VERSION ""

NS_ :

BS_:

BU_: EON RDC SZL VGSG Gate1 RFK FLA RAD1 CAS CID AHM HKL HUD EKP DWA DSC SM_BF GWS VDM DDE1 ACI CCC SM_FA CTM LDM RSE MRSZ VDA EDCK ZBE EGS ACC Kombi IHKA ARS ACSM FZD PGS NVC AFS DME FRMFA EMF FKA VSW EPS PDC DKG SMG EHC SZM KGM Diagnosetool_PT_CAN Diagnosetool_K_CAN_System Vector__XXX XXX ABS DIA FRM RAD TEL

CM_ "Source <https://github.com/dzid26/opendbc-BMW-E8x-E9x>";
CM_ "Some data copied from https://github.com/HeinrichG-V12/E65_ReverseEngineering/ and MSD81 document"
CM_ "Tool32 reference https://www.bimmerforums.com/forum/showthread.php?2298830-E90-Can-bus-project-(E60-E65-E87-)&p=29628499#post29628499"
CM_ "Some data copied from great MK60e5_Development_DBC.dbc: https://www.m5board.com/posts/7693749/"
CM_ "License MIT";
CM_ "BMW E90 K-CAN 100 kbit/s";
CM_ "Additional signals merged from https://github.com/nberlette/canbus";

BO_ 128 SYNC: 5 XXX
 SG_ State1 : 16|8@1+ (1,0) [0|255] "" Vector__XXX
 SG_ State2 : 24|4@1+ (1,0) [0|15] "" Vector__XXX
 SG_ Counter_128 : 28|4@1+ (1,0) [0|15] "" Vector__XXX

BO_ 133 Synchronization_SC_VDA: 8 DSC

BO_ 168 EngineAndBrake: 8 DME
 SG_ Checksum_0xa8 : 0|8@1+ (1,0) [0|0] "" EGS,DSC
 SG_ Counter_0xa8 : 8|4@1+ (1,0) [0|15] "" EGS,DSC
 SG_ TORQ_AVL : 12|12@1- (0.5,0) [-1024|1023.5] "Nm" EGS,DSC
 SG_ ST_TORQ_AVL : 27|4@0+ (1,0) [0|15] "" EGS,DSC
 SG_ TORQ_AVL_DMEE : 28|12@1- (0.5,0) [-1024|1023.5] "Nm" EGS,DSC
 SG_ ST_SW_CLT : 41|2@0+ (1,0) [0|3] "" EGS,DSC
 SG_ ST_RTIR : 43|2@0+ (1,0) [0|3] "" EGS,DSC
 SG_ ST_DMEA_SWO : 44|2@1+ (1,0) [0|0] "" EGS,DSC
 SG_ RCPT_ACC_SWO_SYS_DME : 47|2@0+ (1,0) [0|3] "" EGS,DSC
 SG_ ST_RCPT_ENG_ACC : 48|2@1+ (1,0) [0|0] "" EGS,DSC
 SG_ ST_RCPT_ENG_ARS : 50|2@1+ (1,0) [0|0] "" EGS,DSC
 SG_ ST_RCPT_ENG_DSC : 52|2@1+ (1,0) [0|0] "" EGS,DSC
 SG_ ST_RCPT_ENG_EGS : 54|2@1+ (1,0) [0|0] "" EGS,DSC
 SG_ ST_OBD_CTFN_GRB : 60|5@0+ (1,0) [0|31] "" EGS,DSC
 SG_ BrakePressed : 61|1@0+ (1,0) [0|1] "" EGS,DSC
 SG_ BrakeActive : 62|1@0+ (1,0) [0|1] "" EGS,DSC
 SG_ BrakeStatusInvalid : 63|1@1+ (1,0) [0|1] "" EGS,DSC

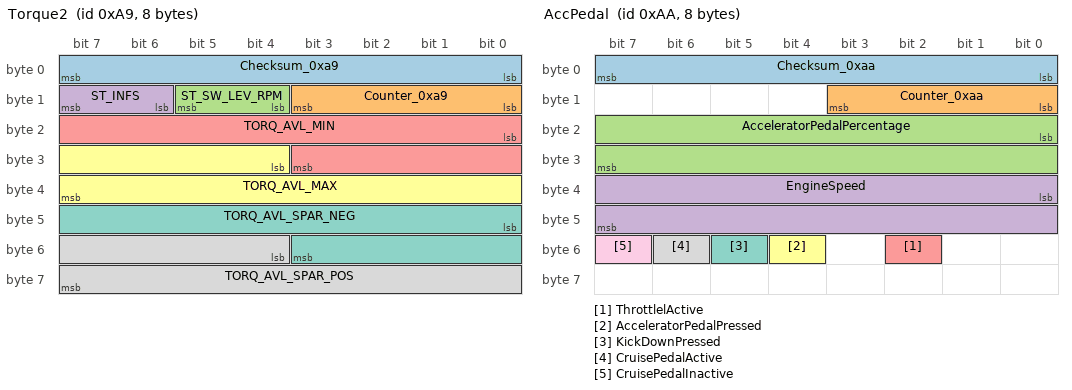
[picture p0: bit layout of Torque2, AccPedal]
BO_ 169 Torque2: 8 DME
 SG_ Checksum_0xa9 : 0|8@1+ (1,0) [0|0] "" EGS,DSC
 SG_ Counter_0xa9 : 8|4@1+ (1,0) [0|0] "" EGS,DSC
 SG_ ST_SW_LEV_RPM : 12|2@1+ (1,0) [0|0] "" EGS,DSC
 SG_ ST_INFS : 14|2@1+ (1,0) [0|0] "" EGS,DSC
 SG_ TORQ_AVL_MIN : 16|12@1- (0.5,0) [-1023.5|1023.5] "Nm" EGS,DSC
 SG_ TORQ_AVL_MAX : 28|12@1- (0.5,0) [-1023.5|1023.5] "Nm" EGS,DSC
 SG_ TORQ_AVL_SPAR_NEG : 40|12@1- (0.5,0) [-1023.5|1023.5] "Nm" EGS,DSC
 SG_ TORQ_AVL_SPAR_POS : 52|12@1- (0.5,0) [-1023.5|1023.5] "Nm" EGS,DSC

BO_ 170 AccPedal: 8 DME
 SG_ Checksum_0xaa : 0|8@1- (1,0) [0|65535] "" EGS,DSC,ACC
 SG_ Counter_0xaa : 8|4@1+ (1,0) [0|14] "" EGS,DSC,ACC
 SG_ AcceleratorPedalPercentage : 16|16@1+ (0.04,0) [0|100] "" EGS,DSC,ACC
 SG_ EngineSpeed : 32|16@1+ (0.25,0) [0|8000] "rpm" EGS,DSC,ACC
 SG_ ThrottlelActive : 50|1@0+ (1,0) [0|1] "" EGS,DSC,ACC
 SG_ AcceleratorPedalPressed : 52|1@0+ (1,0) [0|7] "" EGS,DSC,ACC
 SG_ KickDownPressed : 53|1@0+ (1,0) [0|3] "" EGS,DSC,ACC
 SG_ CruisePedalActive : 54|1@0+ (1,0) [0|1] "" EGS,DSC,ACC
 SG_ CruisePedalInactive : 55|1@0+ (1,0) [0|1] "" EGS,DSC,ACC

BO_ 172 WheelTorqueDrivetrain2: 8 DME

BO_ 173 Delay_request_ACC: 8 LDM

BO_ 177 Torque_request_steering: 8 DSC

BO_ 179 Control_steering_assist: 8 AFS

BO_ 180 WheelTorqueDriveTrain1: 8 DME

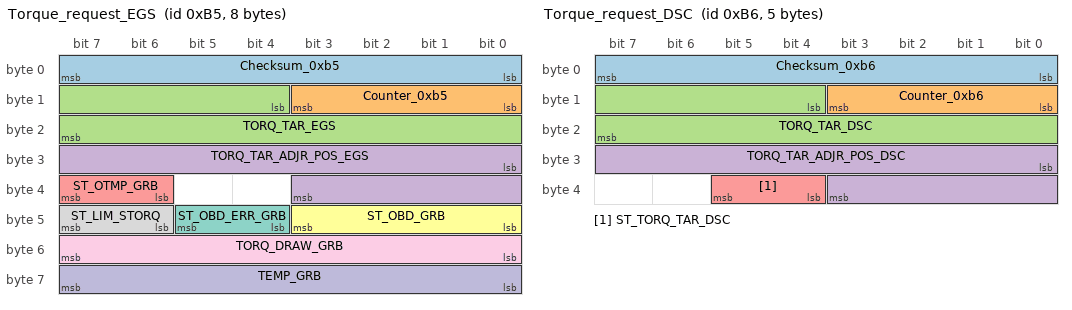
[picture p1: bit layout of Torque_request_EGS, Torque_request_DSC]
BO_ 181 Torque_request_EGS: 8 EGS
 SG_ Checksum_0xb5 : 0|8@1+ (1,0) [0|0] "" DME
 SG_ Counter_0xb5 : 8|4@1+ (1,0) [0|14] "" DME
 SG_ TORQ_TAR_EGS : 12|12@1- (0.5,0) [1024|1023.5] "Nm" DME
 SG_ TORQ_TAR_ADJR_POS_EGS : 24|12@1- (0.5,0) [1024|1023.5] "Nm" DME
 SG_ ST_OTMP_GRB : 38|2@1+ (1,0) [0|3] "" DME
 SG_ ST_OBD_GRB : 40|4@1+ (1,0) [0|15] "" DME
 SG_ ST_OBD_ERR_GRB : 44|2@1+ (1,0) [0|3] "" DME
 SG_ ST_LIM_STORQ : 46|2@1+ (1,0) [0|3] "" DME
 SG_ TORQ_DRAW_GRB : 48|8@1+ (0.5,0) [0|255] "Nm" DME
 SG_ TEMP_GRB : 56|8@1+ (1,-40) [-40|215] "degC" DME

BO_ 182 Torque_request_DSC: 5 DSC
 SG_ Checksum_0xb6 : 0|8@1+ (1,0) [0|255] "" DME
 SG_ Counter_0xb6 : 8|4@1+ (1,0) [0|14] "" DME
 SG_ TORQ_TAR_DSC : 12|12@1- (0.5,0) [1024|1023.5] "Nm" DME
 SG_ TORQ_TAR_ADJR_POS_DSC : 24|12@1- (0.5,0) [1024|1023.5] "Nm" DME
 SG_ ST_TORQ_TAR_DSC : 36|2@1+ (1,0) [0|3] "" DME

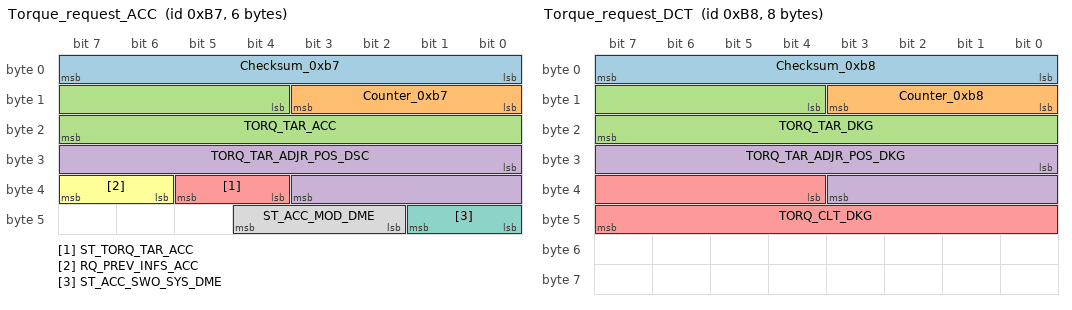
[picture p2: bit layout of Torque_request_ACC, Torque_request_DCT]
BO_ 183 Torque_request_ACC: 6 LDM
 SG_ Checksum_0xb7 : 0|8@1+ (1,0) [0|255] "" DME
 SG_ Counter_0xb7 : 8|4@1+ (1,0) [0|14] "" DME
 SG_ TORQ_TAR_ACC : 12|12@1- (0.5,0) [1024|1023.5] "Nm" DME
 SG_ TORQ_TAR_ADJR_POS_DSC : 24|12@1- (0.5,0) [1024|1023.5] "Nm" DME
 SG_ ST_TORQ_TAR_ACC : 36|2@1+ (1,0) [0|3] "" DME
 SG_ RQ_PREV_INFS_ACC : 38|2@1+ (1,0) [0|3] "" DME
 SG_ ST_ACC_SWO_SYS_DME : 40|2@1+ (1,0) [0|3] "" DME
 SG_ ST_ACC_MOD_DME : 42|3@1+ (1,0) [0|7] "" DME

BO_ 184 Torque_request_DCT: 8 DKG
 SG_ Checksum_0xb8 : 0|8@1+ (1,0) [0|255] "" DME
 SG_ Counter_0xb8 : 8|4@1+ (1,0) [0|14] "" DME
 SG_ TORQ_TAR_DKG : 12|12@1- (0.5,0) [-1024|1023.5] "Nm" DME
 SG_ TORQ_TAR_ADJR_POS_DKG : 24|12@1- (0.5,0) [-1024|1023.5] "Nm" DME
 SG_ TORQ_CLT_DKG : 36|12@1- (1,0) [0|0] "" DME

BO_ 185 Torque_request_AFS: 8 AFS

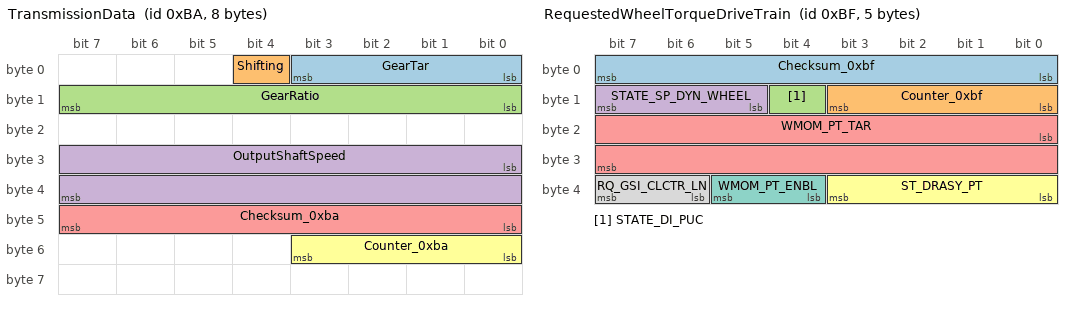
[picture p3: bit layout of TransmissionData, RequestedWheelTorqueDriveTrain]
BO_ 186 TransmissionData: 8 EGS
 SG_ GearTar : 0|4@1+ (1,-4) [0|0] "" DME,DSC
 SG_ Shifting : 4|1@1+ (1,0) [0|1] "" DME,DSC
 SG_ GearRatio : 8|8@1+ (0.05,0) [0|255] "" DME,DSC
 SG_ OutputShaftSpeed : 24|16@1- (0.125,0) [0|0] "rpm" DME,DSC
 SG_ Checksum_0xba : 40|8@1+ (1,0) [0|255] "" DME,DSC
 SG_ Counter_0xba : 48|4@1+ (1,0) [0|14] "" DME,DSC

BO_ 187 Target_torque_request: 8 DSC

BO_ 188 Status_target_torque_conversion: 8 VGSG

BO_ 189 Torque_request_SSG: 8 SMG

BO_ 190 Alive_Counter: 8 ARS

BO_ 191 RequestedWheelTorqueDriveTrain: 5 DSC_LDM
 SG_ Checksum_0xbf : 0|8@1+ (1,0) [0|255] "" DME
 SG_ Counter_0xbf : 8|4@1- (1,0) [0|15] "" DME
 SG_ STATE_DI_PUC : 12|1@1+ (1,0) [0|1] "" XXX
 SG_ STATE_SP_DYN_WHEEL : 13|3@1+ (1,0) [0|7] "" XXX
 SG_ WMOM_PT_TAR : 16|16@1+ (1,-32000) [-32000|32000] "Nm" DME
 SG_ ST_DRASY_PT : 32|4@1+ (1,0) [0|15] "" DME
 SG_ WMOM_PT_ENBL : 36|2@1+ (1,0) [0|3] "" DME
 SG_ RQ_GSI_CLCTR_LN : 38|2@1+ (1,0) [0|3] "" DME

BO_ 192 Alive_Central_Gateway: 8 Gate1

BO_ 193 Alive_counter_telephone: 8 CCC

BO_ 196 SteeringWheelAngle: 7 DSC
 SG_ SteeringPosition : 0|16@1- (0.04395,0) [-600|600] "deg" EPS,DME,ACC
 SG_ SteeringSpeed : 24|16@1- (0.04395,0) [0|0] "deg/s" EPS,DME,ACC

BO_ 200 SteeringWheelAngle_slow: 6 SZL
 SG_ SteeringPosition : 0|16@1- (0.04395,0) [-600|600] "deg" DSC,EPS,ACC
 SG_ Counter_0xc8 : 20|4@1+ (1,0) [0|15] "" DSC,EPS,ACC
 SG_ SteeringSpeed : 24|16@1- (0.04395,0) [-65535|65535] "deg/s" DSC,EPS,ACC

BO_ 201 SteeringWheelAngle_DSC: 8 SZL
 SG_ SteeringPosition : 0|16@1- (0.04395,0) [-600|600] "deg" DSC
 SG_ Counter_0xc9 : 20|4@1+ (1,0) [0|15] "" DSC
 SG_ SteeringPositionComplementLow : 24|11@1- (1,0) [0|1] "" DSC

BO_ 205 Accelerometer2: 8 XXX
 SG_ YawRate : 0|16@1- (1,0) [0|0] "" DSC,ACSM
 SG_ Checksum_0xcd : 16|16@1- (1,0) [0|65535] "" DSC,ACSM
 SG_ LateralAcceleration : 32|16@1- (1,0) [0|0] "" DSC,ACSM
 SG_ Counter_0xcd : 52|4@1+ (1,0) [0|15] "" DSC,ACSM

BO_ 206 WheelSpeeds: 8 DSC
 SG_ Wheel_FL : 0|16@1- (0.0625,0) [0|0] "km/h" DME,EGS,Kombi,ACC
 SG_ Wheel_FR : 16|16@1- (0.0625,0) [0|0] "km/h" DME,EGS,Kombi,ACC
 SG_ Wheel_RL : 32|16@1- (0.0625,0) [0|0] "km/h" DME,EGS,Kombi,ACC
 SG_ Wheel_RR : 48|16@1- (0.0625,0) [0|0] "km/h" DME,EGS,Kombi,ACC

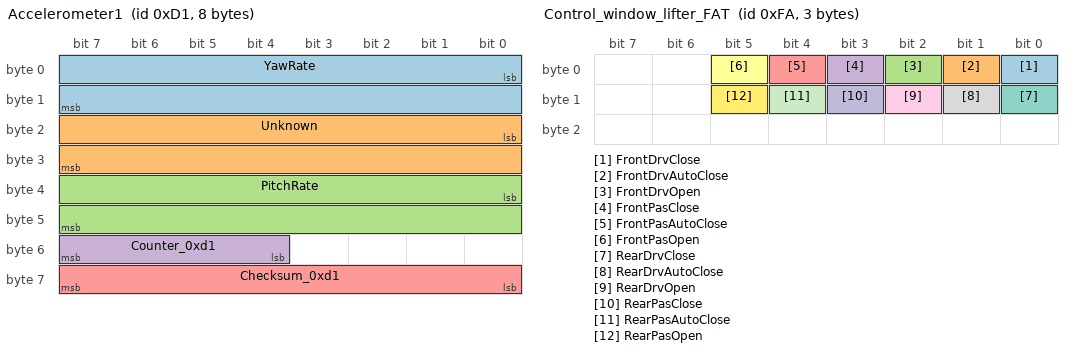
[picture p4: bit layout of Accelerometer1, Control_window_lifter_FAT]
BO_ 209 Accelerometer1: 8 XXX
 SG_ YawRate : 0|16@1- (1,0) [0|0] "" DSC,ACSM
 SG_ Unknown : 16|16@1- (1,0) [0|65535] "" DSC,ACSM
 SG_ PitchRate : 32|16@1- (1,0) [0|65535] "" DSC,ACSM
 SG_ Counter_0xd1 : 52|4@1+ (1,0) [0|15] "" DSC,ACSM
 SG_ Checksum_0xd1 : 56|8@1+ (1,0) [0|255] "" DSC,ACSM

BO_ 212 Unknown_d4: 8 XXX
 SG_ State1 : 40|8@1+ (1,0) [0|255] "" Vector__XXX
 SG_ Counter_0xd4 : 52|4@1+ (1,0) [0|15] "" Vector__XXX
 SG_ Checksum_0xd4 : 56|8@1+ (1,0) [0|255] "" Vector__XXX

BO_ 213 Request_wheel_torque_brake: 8 LDM
 SG_ Checksum_0xd5 : 0|8@1+ (1,0) [0|255] "" DSC
 SG_ Counter_0xd5 : 8|4@1- (1,0) [0|15] "" DSC

BO_ 215 Alive_Counter_Security: 8 ACSM

BO_ 216 CLU1_VDA: 8 VDA

BO_ 225 Wheel_torque_brake: 8 DSC

BO_ 226 Status_central_locking_BFT: 8 Gate1
 SG_ DoorLockStatus_BFT : 0|8@1+ (1,0) [0|255] "" CAS,Kombi
 SG_ DoorOpenStatus_BFT : 24|8@1+ (1,0) [0|255] "" CAS,Kombi

BO_ 227 CLU2_VDA: 8 VDA

BO_ 230 Status_central_locking_BFTH: 8 Gate1
 SG_ DoorLockStatus_BFTH : 0|8@1+ (1,0) [0|255] "" CAS,Kombi
 SG_ DoorOpenStatus_BFTH : 24|8@1+ (1,0) [0|255] "" CAS,Kombi

BO_ 234 Status_central_locking_FAT: 8 Gate1
 SG_ DoorLockStatus_FAT : 0|8@1+ (1,0) [0|255] "" CAS,Kombi
 SG_ DoorOpenStatus_FAT : 24|8@1+ (1,0) [0|255] "" CAS,Kombi

BO_ 238 Central_locking_status_FATH: 8 Gate1
 SG_ DoorLockStatus_FATH : 0|8@1+ (1,0) [0|255] "" CAS,Kombi
 SG_ DoorOpenStatus_FATH : 24|8@1+ (1,0) [0|255] "" CAS,Kombi

BO_ 242 Status_central_locking_HK: 8 Gate1
 SG_ BootLockStatus : 0|8@1+ (1,0) [0|255] "" CAS,Kombi
 SG_ BootReleaseButton : 16|8@1+ (1,0) [0|255] "" CAS,Kombi
 SG_ BootOpenStatus : 24|8@1+ (1,0) [0|255] "" CAS,Kombi

BO_ 244 CLU3_VDA: 8 VDA

BO_ 246 MirrorControl_0F6: 2 KGM

BO_ 247 lateral_dynamics_ARS_VDM: 8 ARS

BO_ 249 Vertical_dynamics_VDM_ARS: 8 VDM

BO_ 250 Control_window_lifter_FAT: 3 FRMFA
 SG_ FrontDrvClose : 0|1@1+ (1,0) [0|1] "" Gate1
 SG_ FrontDrvAutoClose : 1|1@1+ (1,0) [0|1] "" Gate1
 SG_ FrontDrvOpen : 2|1@1+ (1,0) [0|1] "" Gate1
 SG_ FrontPasClose : 3|1@1+ (1,0) [0|1] "" Gate1
 SG_ FrontPasAutoClose : 4|1@1+ (1,0) [0|1] "" Gate1
 SG_ FrontPasOpen : 5|1@1+ (1,0) [0|1] "" Gate1
 SG_ RearDrvClose : 8|1@1+ (1,0) [0|1] "" Gate1
 SG_ RearDrvAutoClose : 9|1@1+ (1,0) [0|1] "" Gate1
 SG_ RearDrvOpen : 10|1@1+ (1,0) [0|1] "" Gate1
 SG_ RearPasClose : 11|1@1+ (1,0) [0|1] "" Gate1
 SG_ RearPasAutoClose : 12|1@1+ (1,0) [0|1] "" Gate1
 SG_ RearPasOpen : 13|1@1+ (1,0) [0|1] "" Gate1

BO_ 251 Control_window_lifter_BFT: 8 Gate1

BO_ 252 Control_window_lifter_FATH: 8 Gate1

BO_ 253 Control_window_lifter_BFTH: 8 Gate1

BO_ 254 Voltage_level_sensors: 8 VDM

BO_ 280 Exchange_AFS_DSC: 8 AFS

BO_ 286 Control_interventions_DSC_AFS: 8 DSC

BO_ 288 Status_partial_setpoints_AFS_DSC_2: 8 AFS

BO_ 298 Sensor_data_ROSE: 8 ASCM

BO_ 300 input_data_ROSE: 8 DSC

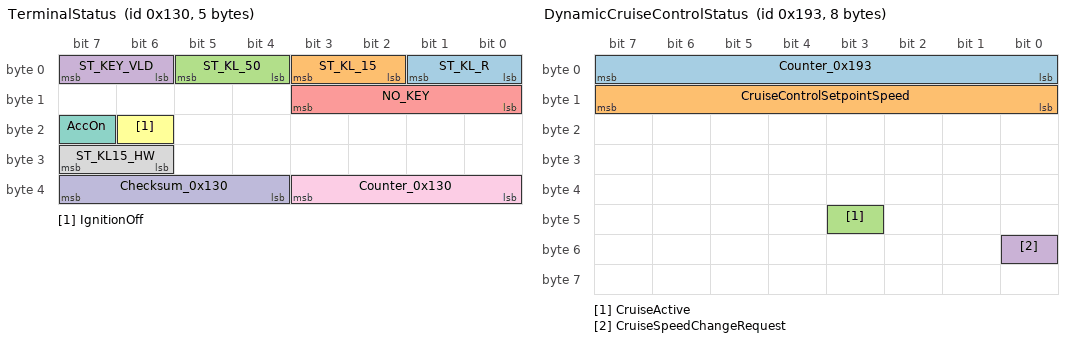
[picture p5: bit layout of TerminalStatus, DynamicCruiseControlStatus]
BO_ 304 TerminalStatus: 5 CAS
 SG_ ST_KL_R : 1|2@0+ (1,0) [0|3] "" DME,EGS,FRMFA,Kombi,CIC,IHKA
 SG_ ST_KL_15 : 3|2@0+ (1,0) [0|1] "" DME,EGS,FRMFA,Kombi,CIC,IHKA
 SG_ ST_KL_50 : 5|2@0+ (1,0) [0|3] "" DME,EGS,FRMFA,Kombi,CIC,IHKA
 SG_ ST_KEY_VLD : 7|2@0+ (1,0) [0|3] "" DME,EGS,FRMFA,Kombi,CIC,IHKA
 SG_ NO_KEY : 11|4@0+ (1,0) [0|15] "" DME,EGS,FRMFA,Kombi,CIC,IHKA
 SG_ IgnitionOff : 22|1@1+ (1,0) [0|3] "" DME,EGS,FRMFA,Kombi,CIC,IHKA
 SG_ AccOn : 23|1@1+ (1,0) [0|255] "" DME,EGS,FRMFA,Kombi,CIC,IHKA
 SG_ ST_KL15_HW : 31|2@0+ (1,0) [0|3] "" DME,EGS,FRMFA,Kombi,CIC,IHKA
 SG_ Counter_0x130 : 32|4@1+ (1,0) [0|15] "" DME,EGS,FRMFA,Kombi,CIC,IHKA
 SG_ Checksum_0x130 : 36|4@1+ (1,0) [0|255] "" DME,EGS,FRMFA,Kombi,CIC,IHKA

BO_ 309 CrashDisconnectControl: 8 ACSM

BO_ 320 Unknown140: 2 XXX
 SG_ State : 7|8@0+ (1,0) [0|255] "" Vector__XXX

BO_ 336 Request_1_ACC: 8 LDM
 SG_ Checksum_0x150 : 0|8@1+ (1,0) [0|255] "" ACC
 SG_ Counter_0x150 : 8|4@1- (1,0) [0|15] "" ACC

BO_ 339 Request_2_ACC: 8 LDM
 SG_ Checksum_0x153 : 0|8@1+ (1,0) [0|255] "" ACC
 SG_ Counter_0x153 : 8|4@1- (1,0) [0|15] "" ACC

BO_ 345 Object_data_ACC: 8 ACC
 SG_ Checksum_0x159 : 0|8@1+ (1,0) [0|255] "" LDM
 SG_ Counter_0x159 : 8|4@1- (1,0) [0|15] "" LDM

BO_ 348 Status_ACC: 8 ACC
 SG_ Checksum_0x15c : 0|8@1+ (1,0) [0|255] "" LDM
 SG_ Counter_0x15c : 8|4@1- (1,0) [0|15] "" LDM

BO_ 351 Requirement_angle_FFP: 8 LDM

BO_ 357 CLU_Status_VDA: 8 VDA

BO_ 370 Acknowledgment_request_Kombination: 8 CCC
 SG_ CCM_Counter : 0|1@1+ (1,0) [0|1] "" CIC
 SG_ ActiveFaultCount : 16|8@1+ (1,0) [0|255] "" CIC

BO_ 373 Display_motor_data: 3 DME
 SG_ Counter_0x175 : 3|4@0+ (1,0) [0|15] "" Kombi,CIC

BO_ 400 display_ACC: 8 LDM

BO_ 402 GearSelectorSwitch_1: 4 SZL_LWS
 SG_ Counter_0x192 : 24|4@1+ (1,0) [0|14] "" EGS,DME

BO_ 403 DynamicCruiseControlStatus: 8 DSC
 SG_ Counter_0x193 : 7|8@0+ (1,0) [0|15] "" ACC,Kombi
 SG_ CruiseControlSetpointSpeed : 15|8@0+ (1,-2) [0|253] "km/h" ACC,Kombi
 SG_ CruiseActive : 43|1@0+ (1,0) [0|1] "" ACC,Kombi
 SG_ CruiseSpeedChangeRequest : 48|1@0+ (1,0) [0|1] "" ACC,Kombi

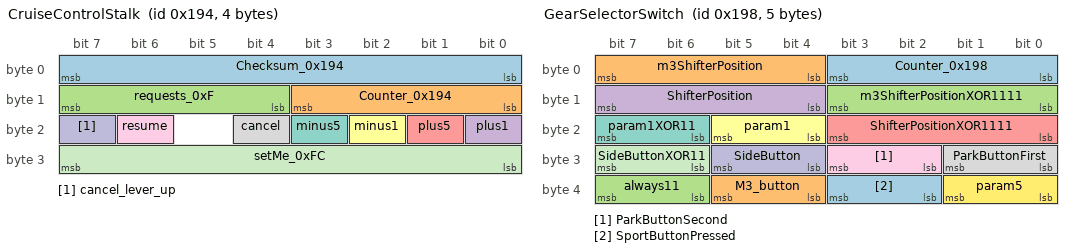
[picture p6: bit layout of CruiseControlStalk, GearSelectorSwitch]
BO_ 404 CruiseControlStalk: 4 SZL
 SG_ Checksum_0x194 : 7|8@0+ (1,0) [0|255] "" ACC,DME,Kombi
 SG_ Counter_0x194 : 11|4@0+ (1,0) [0|14] "" ACC,DME,Kombi
 SG_ requests_0xF : 15|4@0+ (1,0) [0|15] "" ACC,DME,Kombi
 SG_ plus1 : 16|1@0+ (1,0) [0|1] "" ACC,DME,Kombi
 SG_ plus5 : 17|1@0+ (1,0) [0|1] "" ACC,DME,Kombi
 SG_ minus1 : 18|1@0+ (1,0) [0|1] "" ACC,DME,Kombi
 SG_ minus5 : 19|1@0+ (1,0) [0|1] "" ACC,DME,Kombi
 SG_ cancel : 20|1@0+ (1,0) [0|1] "" ACC,DME,Kombi
 SG_ resume : 22|1@0+ (1,0) [0|1] "" ACC,DME,Kombi
 SG_ cancel_lever_up : 23|1@0+ (1,0) [0|1] "" ACC,DME,Kombi
 SG_ setMe_0xFC : 31|8@0+ (1,0) [255|255] "" ACC,DME,Kombi

BO_ 405 Operation_push_button_MSA: 8 IHKA

BO_ 408 GearSelectorSwitch: 5 GWS
 SG_ Counter_0x198 : 0|4@1+ (1,0) [0|14] "" EGS,DME,Kombi
 SG_ m3ShifterPosition : 4|4@1+ (1,0) [0|15] "" EGS,DME,Kombi
 SG_ m3ShifterPositionXOR1111 : 8|4@1+ (1,0) [0|15] "" EGS,DME,Kombi
 SG_ ShifterPosition : 12|4@1+ (1,0) [0|0] "" EGS,DME,Kombi
 SG_ ShifterPositionXOR1111 : 16|4@1+ (1,0) [0|15] "" EGS,DME,Kombi
 SG_ param1 : 20|2@1+ (1,0) [0|3] "" EGS,DME,Kombi
 SG_ param1XOR11 : 22|2@1+ (1,0) [0|3] "" EGS,DME,Kombi
 SG_ ParkButtonFirst : 24|2@1+ (1,0) [0|3] "" EGS,DME,Kombi
 SG_ ParkButtonSecond : 26|2@1+ (1,0) [0|3] "" EGS,DME,Kombi
 SG_ SideButton : 28|2@1+ (1,0) [0|3] "" EGS,DME,Kombi
 SG_ SideButtonXOR11 : 30|2@1+ (1,0) [0|3] "" EGS,DME,Kombi
 SG_ param5 : 32|2@1+ (1,0) [0|3] "" EGS,DME,Kombi
 SG_ SportButtonPressed : 34|2@1+ (1,0) [0|255] "" EGS,DME,Kombi
 SG_ M3_button : 36|2@1+ (1,0) [0|3] "" EGS,DME,Kombi
 SG_ always11 : 38|2@1+ (1,0) [0|3] "" EGS,DME,Kombi

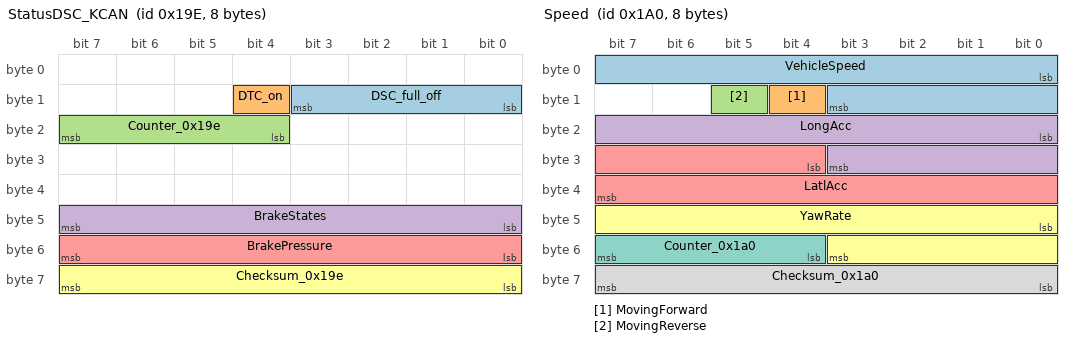
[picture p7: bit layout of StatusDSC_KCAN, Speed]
BO_ 414 StatusDSC_KCAN: 8 DSC
 SG_ DSC_full_off : 8|4@1+ (1,0) [0|1] "" Kombi,CIC
 SG_ DTC_on : 12|1@1+ (1,0) [0|1] "" Kombi,CIC
 SG_ Counter_0x19e : 20|4@1+ (1,0) [0|15] "" Kombi,CIC
 SG_ BrakeStates : 40|8@1+ (1,0) [0|255] "" Kombi,CIC
 SG_ BrakePressure : 48|8@1- (1,0) [0|0] "" Kombi,CIC
 SG_ Checksum_0x19e : 56|8@1+ (1,0) [0|255] "" Kombi,CIC

BO_ 416 Speed: 8 DSC
 SG_ VehicleSpeed : 0|12@1- (0.103,0) [0|0] "km/h" Kombi,CIC,IHKA,ACC
 SG_ MovingForward : 12|1@1+ (1,0) [0|1] "" Kombi,CIC,IHKA,ACC
 SG_ MovingReverse : 13|1@1+ (1,0) [0|1] "" Kombi,CIC,IHKA,ACC
 SG_ LongAcc : 16|12@1- (0.025,0) [0|0] "m/s^2" Kombi,CIC,IHKA,ACC
 SG_ LatlAcc : 28|12@1- (0.025,0) [0|0] "m/s^2" Kombi,CIC,IHKA,ACC
 SG_ YawRate : 40|12@1- (0.05,0) [0|0] "deg/s" Kombi,CIC,IHKA,ACC
 SG_ Counter_0x1a0 : 52|4@1+ (1,0) [0|14] "" Kombi,CIC,IHKA,ACC
 SG_ Checksum_0x1a0 : 56|8@1+ (1,0) [0|255] "" Kombi,CIC,IHKA,ACC

BO_ 417 SpeedKombi_1A1: 5 XXX
 SG_ SpeedKmh_1A1 : 23|16@0+ (0.0160934,0) [0|1054.4] "km/h" Kombi,CIC

BO_ 418 TransimissionData2: 8 EGS
 SG_ Counter_0x1a2 : 28|4@1+ (1,0) [0|14] "" DME,Kombi
 SG_ ManualMode : 50|1@0+ (1,0) [0|1] "" DME,Kombi
 SG_ Checksum_0x1a2 : 56|8@1+ (1,0) [0|255] "" DME,Kombi

BO_ 419 Raw_data_longitudinal_acceleration: 8 DSC

BO_ 422 DistanceRoute: 8 DSC
 SG_ SpeedCounter1 : 0|16@1+ (1,0) [0|65535] "" Kombi
 SG_ SpeedCounter2 : 16|16@1+ (1,0) [0|65535] "" Kombi
 SG_ SpeedCounter3 : 32|16@1+ (1,0) [0|65535] "" Kombi
 SG_ TimeCounter : 48|16@1+ (1,0) [0|65535] "" Kombi

BO_ 423 actuation_request_EMF: 8 DSC

BO_ 426 Effect_ErgoCommander: 8 CCC

BO_ 428 Status_ARS_module: 8 ARS

BO_ 436 InstrumentClusterStatus_KOMBI: 8 CCC
 SG_ HandbrakeActive : 41|1@1+ (1,0) [0|1] "" Kombi

BO_ 437 HeatFlow_LoadTorqueClimate: 7 IHKA

BO_ 438 HeatFlowEngine: 7 DME

BO_ 440 Operation_ErgoCommander: 8 ZBE

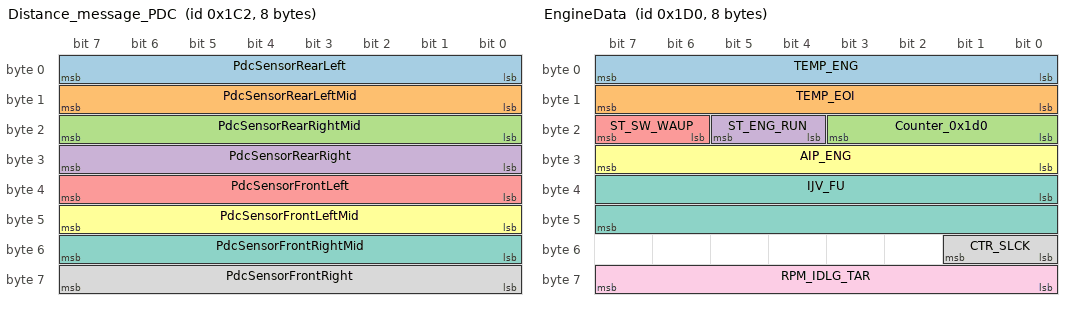
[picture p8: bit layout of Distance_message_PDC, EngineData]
BO_ 450 Distance_message_PDC: 8 PDC
 SG_ PdcSensorRearLeft : 0|8@1+ (1,0) [0|255] "cm" CIC,Kombi
 SG_ PdcSensorRearLeftMid : 8|8@1+ (1,0) [0|255] "cm" CIC,Kombi
 SG_ PdcSensorRearRightMid : 16|8@1+ (1,0) [0|255] "cm" CIC,Kombi
 SG_ PdcSensorRearRight : 24|8@1+ (1,0) [0|255] "cm" CIC,Kombi
 SG_ PdcSensorFrontLeft : 32|8@1+ (1,0) [0|255] "cm" CIC,Kombi
 SG_ PdcSensorFrontLeftMid : 40|8@1+ (1,0) [0|255] "cm" CIC,Kombi
 SG_ PdcSensorFrontRightMid : 48|8@1+ (1,0) [0|255] "cm" CIC,Kombi
 SG_ PdcSensorFrontRight : 56|8@1+ (1,0) [0|255] "cm" CIC,Kombi

BO_ 451 Distance_message_2_PDC: 8 PDC

BO_ 454 Acoustic_message_PDC: 8 PDC

BO_ 464 EngineData: 8 DME
 SG_ TEMP_ENG : 0|8@1+ (1,-48) [0|0] "degC"Kombi,CIC
 SG_ TEMP_EOI : 8|8@1+ (1,-48) [0|0] "degC"Kombi,CIC
 SG_ Counter_0x1d0 : 16|4@1+ (1,0) [0|14] "" Kombi,CIC
 SG_ ST_ENG_RUN : 20|2@1+ (1,0) [0|0] "" Kombi,CIC
 SG_ ST_SW_WAUP : 22|2@1+ (1,0) [0|0] "" Kombi,CIC
 SG_ AIP_ENG : 24|8@1+ (2,598) [600|1106] "hPa" Kombi,CIC
 SG_ IJV_FU : 32|16@1+ (1,-48) [0|0] "degC"Kombi,CIC
 SG_ CTR_SLCK : 48|2@1+ (1,0) [0|0] "" Kombi,CIC
 SG_ RPM_IDLG_TAR : 56|8@1+ (5,0) [0|1270] "rpm"Kombi,CIC

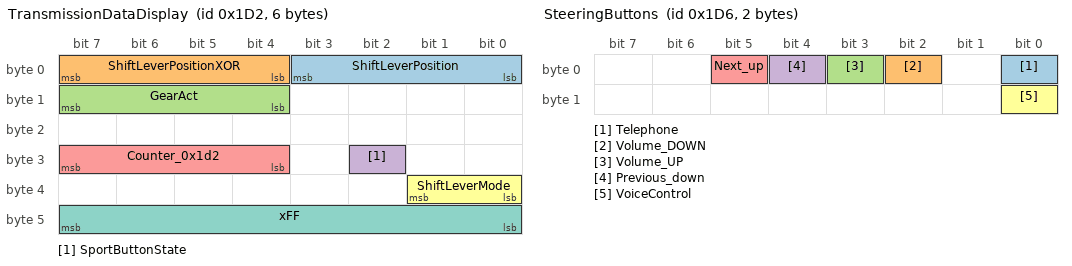
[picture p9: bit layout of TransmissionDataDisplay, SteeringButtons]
BO_ 466 TransmissionDataDisplay: 6 EGS
 SG_ ShiftLeverPosition : 0|4@1+ (1,0) [0|8] "" Kombi,CIC
 SG_ ShiftLeverPositionXOR : 4|4@1+ (1,0) [0|0] "" Kombi,CIC
 SG_ GearAct : 12|4@1+ (1,-4) [0|15] "" Kombi,CIC
 SG_ SportButtonState : 26|1@1+ (1,0) [0|1] "" Kombi,CIC
 SG_ Counter_0x1d2 : 28|4@1+ (1,0) [0|14] "" Kombi,CIC
 SG_ ShiftLeverMode : 32|2@1+ (1,0) [0|3] "" Kombi,CIC
 SG_ xFF : 40|8@1+ (1,0) [0|255] "" Kombi,CIC

BO_ 470 SteeringButtons: 2 SZL
 SG_ Telephone : 0|1@0+ (1,0) [0|1] "" CIC,Kombi
 SG_ Volume_DOWN : 2|1@0+ (1,0) [0|1] "" CIC,Kombi
 SG_ Volume_UP : 3|1@0+ (1,0) [0|1] "" CIC,Kombi
 SG_ Previous_down : 4|1@0+ (1,0) [0|1] "" CIC,Kombi
 SG_ Next_up : 5|1@0+ (1,0) [0|1] "" CIC,Kombi
 SG_ VoiceControl : 8|1@0+ (1,0) [0|1] "" CIC,Kombi

BO_ 472 Operation_air_conditioning_air_distribution_FA: 8 CCC

BO_ 473 Operation_pushbutton_MDrive: 8 SZL

BO_ 474 Climate_control_remote_control: 8 CAS

BO_ 476 Operation_stratification_seat_heating: 8 CCC

BO_ 478 Air_conditioning_controls_rear: 8 CCC

BO_ 480 Operation_air_conditioning_air_distribution_BF: 8 CCC

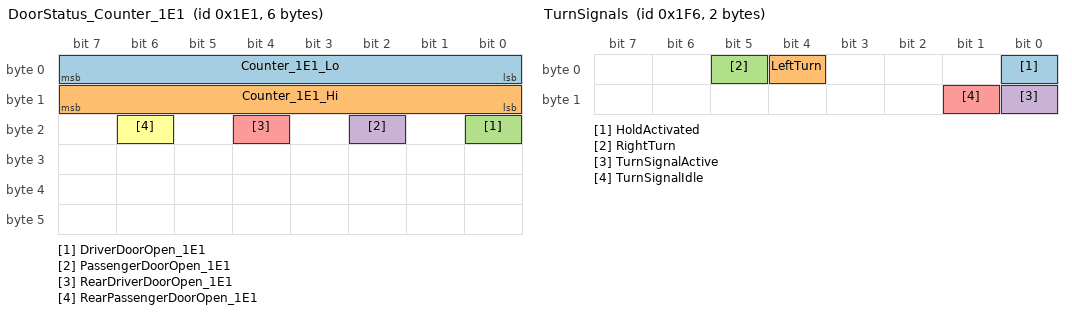
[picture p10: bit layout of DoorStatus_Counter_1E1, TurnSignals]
BO_ 481 DoorStatus_Counter_1E1: 6 XXX
 SG_ Counter_1E1_Lo : 0|8@1+ (1,0) [0|255] "" Gate1,CIC,Kombi
 SG_ Counter_1E1_Hi : 8|8@1+ (1,0) [0|255] "" Gate1,CIC,Kombi
 SG_ DriverDoorOpen_1E1 : 16|1@1+ (1,0) [0|1] "" Gate1,CIC,Kombi
 SG_ PassengerDoorOpen_1E1 : 18|1@1+ (1,0) [0|1] "" Gate1,CIC,Kombi
 SG_ RearDriverDoorOpen_1E1 : 20|1@1+ (1,0) [0|1] "" Gate1,CIC,Kombi
 SG_ RearPassengerDoorOpen_1E1 : 22|1@1+ (1,0) [0|1] "" Gate1,CIC,Kombi

BO_ 482 Operation_air_conditioning_front: 8 CCC

BO_ 483 Operation_pushbutton_interior_lighting: 8 FZD

BO_ 487 Operation_seat_heating_seat_climate_FA: 8 IHKA

BO_ 488 Operation_seat_heating_seat_climate_BF: 8 IHKA

BO_ 490 Steering_column_adjustment_control: 8 IHKA

BO_ 491 Operation_active_seat_FA: 8 IHKA

BO_ 492 Operation_active_seat_BF: 8 IHKA

BO_ 493 Operation_backrest_adjust_FA: 8 SZM

BO_ 494 Steering_column_switch_operation: 8 FRMFA
 SG_ IndicatorStalkPos : 0|8@1+ (1,0) [0|255] "" Kombi,CIC

BO_ 495 Operation_backrest_adjust_BF: 8 SZM

BO_ 498 Operation_seat_memory_BF: 8 SZM

BO_ 499 Operation_seat_memory_FA: 8 SZM

BO_ 502 TurnSignals: 2 FRMFA
 SG_ HoldActivated : 0|1@1+ (1,0) [0|1] "" Kombi,FRMFA
 SG_ LeftTurn : 4|1@1+ (1,0) [0|1] "" Kombi,FRMFA
 SG_ RightTurn : 5|1@0+ (1,0) [0|1] "" Kombi,FRMFA
 SG_ TurnSignalActive : 8|1@0+ (1,0) [0|1] "" Kombi,FRMFA
 SG_ TurnSignalIdle : 9|1@0+ (1,0) [0|1] "" Kombi,FRMFA

BO_ 504 Operation_SHD_MDS: 8 FZD

BO_ 507 Status_EPS: 8 EPS

BO_ 508 Status_AFS: 8 AFS

BO_ 509 Status_request_EMF_KCAN: 8 EMF

BO_ 510 Crash: 8 ACSM

BO_ 512 CruiseControlStatus: 8 DME
 SG_ CruiseControlSetpointSpeed : 7|8@0+ (0.402335,0) [0|0] "km/h" Kombi,CIC,ACC
 SG_ CruiseControlInactiveFlag : 12|1@0+ (1,0) [0|1] "" Kombi,CIC,ACC
 SG_ CruiseCoontrolActiveFlag : 13|1@0+ (1,0) [0|1] "" Kombi,CIC,ACC

BO_ 513 Status_EMF_KCAN: 8 EMF

BO_ 514 Dimming: 2 FRMFA

BO_ 517 Acoustic_request_Kombi: 8 Kombi
 SG_ GongCounter : 0|1@1+ (1,0) [0|1] "" Kombi

BO_ 518 Control_Display_Shiftlights: 8 DME

BO_ 523 Memory_adjustment: 8 SM_FA

BO_ 524 Steering_column_control: 8 SM_FA

BO_ 525 Position_steering_column: 8 IHKA

BO_ 528 Operation_HUD: 8 CCC

BO_ 529 Status_HUD: 8 HUD

BO_ 530 Height_levels_air_spring: 8 EHC

BO_ 538 LampStatus: 8 FRMFA
 SG_ LightsByte0 : 0|8@1+ (1,0) [0|255] "" Kombi,CIC
 SG_ LightsByte1 : 8|8@1+ (1,0) [0|255] "" Kombi,CIC

BO_ 540 Operation_NightVision: 8 CCC

BO_ 542 Status_NightVision: 8 NVC

BO_ 548 Operation_push_button_NSW: 8 FRMFA

BO_ 550 RainSensorWiperSpeed: 5 FZD
 SG_ WiperActivity : 0|8@1+ (1,0) [0|255] "" FRMFA,Kombi
 SG_ RainIntensity : 24|8@1+ (1,0) [0|255] "" FRMFA,Kombi

BO_ 552 Operation_special_function: 8 CCC

BO_ 554 Status_BFS: 8 Gate1

BO_ 556 Operation_push_button_NSL: 8 FRMFA

BO_ 562 Status_FAS: 8 Gate1

BO_ 566 Status_FASH: 7 XXX

BO_ 570 Status_radio_key: 8 CAS
 SG_ KeyfobAction : 8|8@1+ (1,0) [0|255] "" CIC,RAD1
 SG_ KeyfobButton : 16|8@1+ (1,0) [0|255] "" CIC,RAD1

BO_ 571 Status_climate_front_extended: 8 IHKA

BO_ 573 Request_display_climate: 8 IHKA

BO_ 574 Status_Klima_Fond: 8 FKA

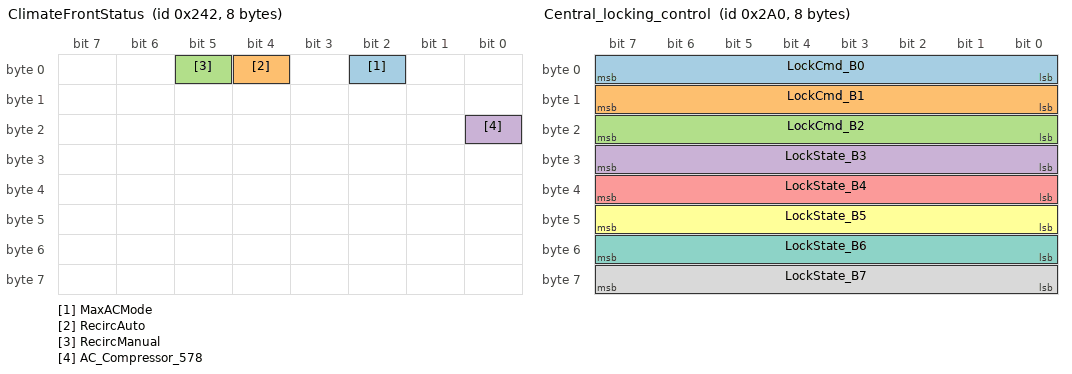
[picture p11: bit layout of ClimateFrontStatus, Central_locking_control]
BO_ 578 ClimateFrontStatus: 8 IHKA
 SG_ MaxACMode : 2|1@1+ (1,0) [0|1] "" CIC,Kombi
 SG_ RecircAuto : 4|1@1+ (1,0) [0|1] "" CIC,Kombi
 SG_ RecircManual : 5|1@1+ (1,0) [0|1] "" CIC,Kombi
 SG_ AC_Compressor_578 : 16|1@1+ (1,0) [0|1] "" CIC,Kombi

BO_ 582 Status_air_conditioning_front_control_unit: 8 IHKA
 SG_ ClimaTempSetpoint : 16|8@1+ (0.5,2.5) [0|73] "degC" CIC

BO_ 584 Status_rear_view_camera: 8 RFK

BO_ 585 Control_rear_view_camera: 8 CCC

BO_ 586 Status_PDC: 8 PDC
 SG_ ReverseGear_24A : 0|8@1+ (1,0) [0|255] "" CIC,Kombi

BO_ 587 Status_door_sensors: 8 FRMFA

BO_ 594 Wiper_status: 8 Gate1
 SG_ WiperStatus : 0|8@1+ (1,0) [0|255] "" Kombi,CIC

BO_ 598 Challenge_Passive_Access: 8 CAS

BO_ 600 Status_Transmission_Passive_Access: 8 PGS

BO_ 604 Operation_of_climate_additional_programs: 8 CCC

BO_ 612 iDrive_Rotary_264: 6 ZBE
 SG_ ByteCounter_264 : 16|8@1+ (1,0) [0|255] "" CIC
 SG_ RotaryAbsoluteLow_264 : 24|8@1+ (1,0) [0|255] "" CIC
 SG_ RotaryAbsoluteHigh_264 : 32|8@1+ (1,0) [0|255] "" CIC

BO_ 615 iDrive_Buttons_267: 6 ZBE
 SG_ ButtonCounter_267 : 16|8@1+ (1,0) [0|255] "" CIC
 SG_ ButtonDirection_267 : 24|8@1+ (1,0) [0|255] "" CIC
 SG_ ButtonArea_267 : 32|8@1+ (1,0) [0|255] "" CIC
 SG_ ButtonSelect_267 : 40|8@1+ (1,0) [0|255] "" CIC

BO_ 619 Operation_blinds_BF: 8 KGM

BO_ 620 Operation_blinds_FA: 8 KGM

BO_ 621 Operation_blinds_MK: 8 IHKA

BO_ 622 Control_FH_SHD_central_comfort: 8 CAS

BO_ 627 CIC_Status_for_Idrive: 8 CCC

BO_ 631 Idrive_Emu_Response_277: 4 XXX
 SG_ ScreenNumberAck : 24|5@1+ (1,0) [0|31] "" CIC

BO_ 632 CIC_278: 8 CIC

BO_ 634 NavGraph_Sync_27A: 4 CCC_GW

BO_ 635 Status_Shiftlights: 8 Kombi

BO_ 637 Status_convertible_top_manual_convertible: 8 CAS

BO_ 638 Status_convertible_top_convertible: 8 CTM

BO_ 639 Status_central_locking_convertible_top: 8 Gate1

BO_ 642 Control_security_vehicle_2: 8 XXX

BO_ 644 Control_remote_start_safety_vehicle: 8 CAS

BO_ 646 Electrochromic_control: 8 FZD

BO_ 652 Pushbutton_vertical_dynamics: 8 GWS

BO_ 653 Operation_pushbutton_sport: 8 GWS

BO_ 656 Control_response_hydrogen_vehicle: 8 XXX

BO_ 658 Control_high_beam_assistant: 8 FLA

BO_ 670 Central_locking_control_for_security_vehicle: 8 XXX

BO_ 671 Remote_control_FondCommander: 8 CAS

BO_ 672 Central_locking_control: 8 CAS
 SG_ LockCmd_B0 : 0|8@1+ (1,0) [0|255] "" Gate1,FRMFA
 SG_ LockCmd_B1 : 8|8@1+ (1,0) [0|255] "" Gate1,FRMFA
 SG_ LockCmd_B2 : 16|8@1+ (1,0) [0|255] "" Gate1,FRMFA
 SG_ LockState_B3 : 24|8@1+ (1,0) [0|255] "" Gate1,FRMFA
 SG_ LockState_B4 : 32|8@1+ (1,0) [0|255] "" Gate1,FRMFA
 SG_ LockState_B5 : 40|8@1+ (1,0) [0|255] "" Gate1,FRMFA
 SG_ LockState_B6 : 48|8@1+ (1,0) [0|255] "" Gate1,FRMFA
 SG_ LockState_B7 : 56|8@1+ (1,0) [0|255] "" Gate1,FRMFA

BO_ 674 Operation_of_climate_stand_functions: 8 CCC

BO_ 676 Operation_personalization: 8 Kombi

BO_ 678 WiperSwitch: 2 SZL
 SG_ WiperSpeedMode : 0|4@1+ (1,0) [0|15] "" FRMFA,Kombi
 SG_ WiperAutoActive : 4|1@1+ (1,0) [0|1] "" FRMFA,Kombi

BO_ 690 WheelPressure_KCAN: 8 DSC

BO_ 691 AccelerationData: 5 DSC
 SG_ Checksum_0x2b3 : 7|8@0+ (1,0) [0|15] "" ACSM,DME
 SG_ Counter_0x2b3 : 8|4@1+ (1,0) [0|15] "" ACSM,DME
 SG_ Deceleration : 12|8@1- (1,0) [0|255] "" ACSM,DME

BO_ 692 DWA_Alarm: 8 DWA

BO_ 694 Control_horn_DWA: 8 DWA

BO_ 696 Operation_onboard_computer: 8 CCC

BO_ 697 Operation_RSE: 8 CCC

BO_ 698 Stopwatch: 8 Kombi

BO_ 701 Request_switching_display: 8 CCC

BO_ 702 Switch_status_display: 8 VSW

BO_ 703 Water_valve_control: 8 IHKA

BO_ 704 LCD_lighting: 3 Kombi

BO_ 706 Temperatur_Ist_Fond: 8 FKA

BO_ 711 Display_Kombination_extended: 8 DME

BO_ 714 Outside_temperature: 8 Kombi
 SG_ OutsideTemp : 0|8@1+ (0.5,-40) [-40|87.5] "degC" CIC,IHKA

BO_ 716 Control_monitor_rear: 8 RSE

BO_ 718 Control_monitor: 8 CCC

BO_ 719 Status_of_auxiliary_water_pump: 8 Gate1

BO_ 720 Status_Sensor_AUC: 8 Gate1

BO_ 721 Status_fitting_window_V: 8 FZD

BO_ 722 Status_pressure_refrigeration_circuit: 8 Gate1

BO_ 723 Status_stratification_rear: 8 Gate1

BO_ 725 Status_heating_rear_window: 8 Gate1
 SG_ RearWindowHeater : 0|1@1+ (1,0) [0|1] "" Kombi,CIC

BO_ 726 Status_valve_air_conditioning_compressor: 8 Gate1
 SG_ ACStatus : 8|8@1+ (1,0) [0|255] "" IHKA

BO_ 730 Status_tailgate_lift: 8 HKL

BO_ 734 Switch_control_display: 8 VSW

BO_ 738 Status_setting_video_night_vision: 8 NVC

BO_ 739 Status_setting_video_rear_view_camera: 8 RFK

BO_ 740 Status_trailer: 8 AHM

BO_ 742 Status_of_air_distribution_FA: 8 IHKA
 SG_ ClimateTemp : 56|8@1+ (0.5,0) [0|127.5] "degC" CIC
 SG_ FanSpeed : 40|8@1+ (1,0) [0|7] "" CIC

BO_ 746 Status_air_distribution_BF: 8 IHKA
 SG_ ClimateTempPassenger : 56|8@1+ (0.5,0) [0|127.5] "degC" CIC

BO_ 750 Status_climate_additional_programs: 8 IHKA

BO_ 752 Status_air_condition_functions: 8 IHKA

BO_ 753 Status_driver_detection: 3 MRSZ

BO_ 755 Display_switching_instruction: 8 DME

BO_ 756 Air_conditioning_control_SH_ZH_auxiliary_water_pump: 8 IHKA

BO_ 758 LightControl: 2 FRMFA
 SG_ FZD_InteriorState : 0|8@1+ (1,0) [0|255] "" Gate1,Kombi

BO_ 759 Units: 8 Kombi

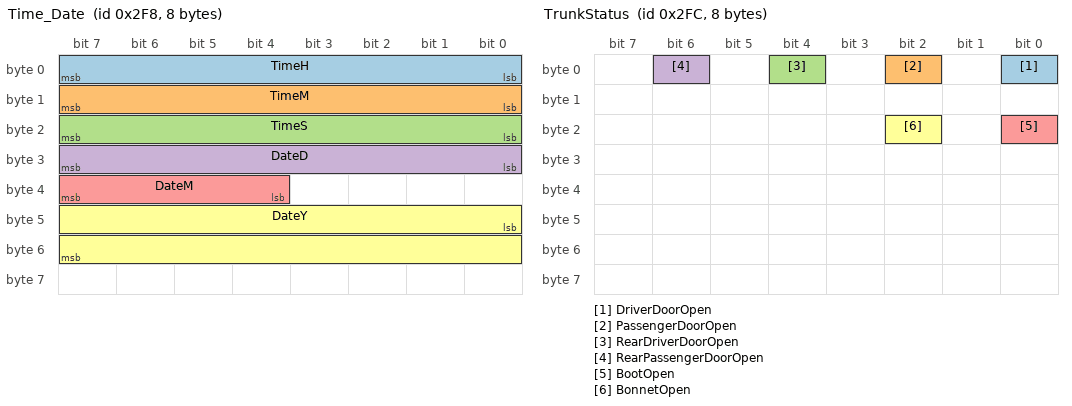
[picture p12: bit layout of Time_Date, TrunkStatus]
BO_ 760 Time_Date: 8 Kombi
 SG_ TimeH : 0|8@1+ (1,0) [0|23] "" CIC,CAS
 SG_ TimeM : 8|8@1+ (1,0) [0|59] "" CIC,CAS
 SG_ TimeS : 16|8@1+ (1,0) [0|59] "" CIC,CAS
 SG_ DateD : 24|8@1+ (1,0) [0|31] "" CIC,CAS
 SG_ DateM : 36|4@1+ (1,0) [0|12] "" CIC,CAS
 SG_ DateY : 40|16@1+ (1,0) [0|2500] "" CIC,CAS

BO_ 762 OccupancySeatBeltContact: 5 ACSM
 SG_ BeltDriver : 0|8@1+ (1,0) [0|255] "" Kombi,DME
 SG_ BeltPassenger : 8|8@1+ (1,0) [0|255] "" Kombi,DME

BO_ 764 TrunkStatus: 8 CAS
 SG_ DriverDoorOpen : 0|1@1+ (1,0) [0|1] "" Gate1,Kombi
 SG_ PassengerDoorOpen : 2|1@1+ (1,0) [0|1] "" Gate1,Kombi
 SG_ RearDriverDoorOpen : 4|1@1+ (1,0) [0|1] "" Gate1,Kombi
 SG_ RearPassengerDoorOpen : 6|1@1+ (1,0) [0|1] "" Gate1,Kombi
 SG_ BootOpen : 16|1@1+ (1,0) [0|1] "" Gate1,Kombi
 SG_ BonnetOpen : 18|1@1+ (1,0) [0|1] "" Gate1,Kombi

BO_ 768 Status_RSE: 8 RSE

BO_ 772 Status_Gang: 8 EGS
 SG_ GearDisplay : 0|8@1+ (1,0) [0|255] "" Kombi,CIC

BO_ 773 Operation_button_convertible_top: 8 IHKA

BO_ 774 Vehicle_tilt: 8 FRMFA

BO_ 775 Operation_button_flap_convertible_top: 8 IHKA

BO_ 776 Status_MSA: 8 DME

BO_ 784 AmbientTemperature_RelativeTime: 8 Kombi

BO_ 785 Refill_quantity: 8 Kombi

BO_ 786 Service_Call_Teleservice: 8 Kombi

BO_ 787 Status_Service_Call_Teleservice: 8 CCC

BO_ 788 Status_driving_light: 8 FZD

BO_ 789 Vehicle_mode: 8 Gate1

BO_ 790 OperationPushButtonDTC: 2 Gate1
 SG_ DTC_pressed : 0|1@1+ (1,0) [0|3] "" DSC
 SG_ setMe_0x3FFF : 2|14@1+ (1,0) [0|63] "" DSC

BO_ 791 Operation_button_parking_aids: 8 IHKA

BO_ 792 Status_antennas_Passive_Access: 8 PGS

BO_ 793 Operation_push_button_RDC: 8 Gate1

BO_ 794 Operation_button_HDC: 8 IHKA

BO_ 795 Operation_of_tailgate_interior_button: 8 IHKA

BO_ 796 Status_tire_pressure: 8 RDC

BO_ 797 TirePressureStatus: 2 DSC

BO_ 801 Operation_button_camera_BF: 8 IHKA

BO_ 802 Damper_current: 8 EDCK

BO_ 806 Status_damper_program: 8 VDM

BO_ 808 Relativzeit: 8 Kombi

BO_ 810 Control_ALC: 2 LM

BO_ 813 Display_HDC: 8 DSC

BO_ 814 Status_climate_internal_control_info: 8 IHKA
 SG_ LightSensor : 0|8@1+ (1,0) [0|16] "" CIC
 SG_ IRTempSensor : 24|8@1+ (0.1,6) [0|31.5] "degC" CIC
 SG_ SolarSensor : 32|8@1+ (1,0) [0|255] "" CIC

BO_ 816 Range_Mileage: 8 Kombi

BO_ 817 Programming_of_step_cruise_control: 8 CCC

BO_ 818 Driver_display_speed_range: 2 DME

BO_ 821 ElectricFuelPumpStatus: 8 EKP

BO_ 822 Display_check_control_message_role: 8 Kombi

BO_ 823 StatusFuelControl: 2 DME

BO_ 824 Control_display_check_control_message: 8 Kombi
 SG_ CCM_Counter : 0|1@1+ (1,0) [0|1] "" CIC
 SG_ ActiveFaultCount : 16|8@1+ (1,0) [0|255] "" CIC

BO_ 825 Status_display_climate: 8 CCC

BO_ 826 Status_Monitor_Front: 8 CID

BO_ 828 Status_Monitor_Fond_1: 8 CID

BO_ 830 Status_Monitor_Fond_2: 8 CID

BO_ 840 NavGraph_Alignment_348: 4 CCC_GW

BO_ 841 Raw_data_level_tank: 8 Gate1
 SG_ FuelSensorLeft : 0|16@1+ (0.006249,0) [0|62.5] "L" Kombi
 SG_ FuelSensorRight : 16|16@1+ (0.006249,0) [0|62.5] "L" Kombi

BO_ 842 GPS_34A: 8 CCC
 SG_ Latitude : 0|32@1- (8.38190317e-08,0) [-90|90] "deg" CIC,Kombi
 SG_ Longitude : 32|32@1- (8.38190317e-08,0) [-180|180] "deg" CIC,Kombi

BO_ 843 Status_seat_back_lock_FA: 8 SM_FA

BO_ 844 NavGraph_GPS2_34C: 5 CCC_GW

BO_ 845 Status_seat_back_lock_BF: 8 SM_BF

BO_ 846 Navi_sys_info: 8 CCC

BO_ 847 Status_contact_handbrake: 2 Gate1
 SG_ Handbrake_pushed_down : 0|1@1+ (1,0) [0|1] "" DSC,Kombi
 SG_ Handbrake_pulled_up : 1|1@1+ (1,0) [0|1] "" DSC,Kombi

BO_ 858 Appointment_Condition_Based_Service: 8 CCC

BO_ 860 Status_onboard_computer: 8 Kombi

BO_ 862 Onboard_computer_data_trip_data: 8 Kombi

BO_ 864 Data_onboard_computer_start_of_journey: 8 Kombi

BO_ 866 Data_onboard_computer_average_values: 8 Kombi

BO_ 868 Data_onboard_computer_arrival: 8 Kombi

BO_ 869 Status_terminal_request: 8 CAS

BO_ 870 Display_Kombination_external_display: 8 Kombi
 SG_ ExternalTemp : 0|8@1+ (0.5,-41) [-40|87.5] "degC" CIC
 SG_ RemainingRange : 8|16@1+ (0.100584,0) [0|6596] "km" CIC

BO_ 871 Control_display_of_demand_oriented_service: 8 Kombi

BO_ 877 Setting_the_driving_dynamics_switch: 8 Gate1

BO_ 884 WheelToleranceAdjustment: 5 DSC

BO_ 886 Status_wear_lamella: 8 VGSG

BO_ 893 Status_DKG: 2 DKG

BO_ 894 Temperatur_Bremse: 8 DSC

BO_ 895 Range_of_diesel_exhaust_gas_additive: 8 DDE1

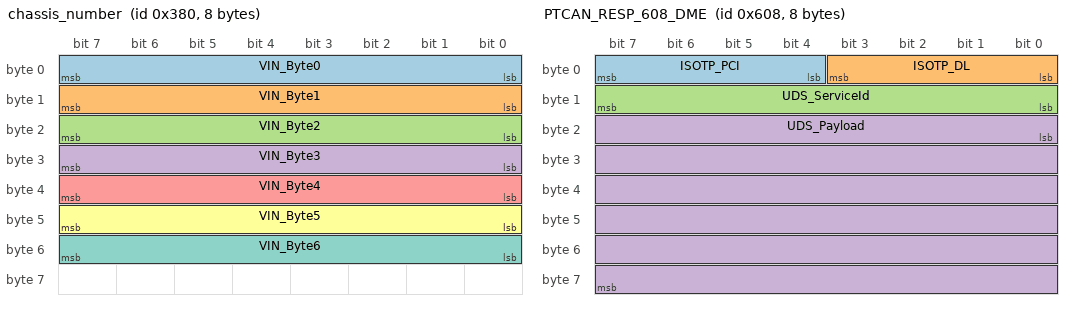
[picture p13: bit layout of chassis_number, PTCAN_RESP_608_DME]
BO_ 896 chassis_number: 8 CAS
 SG_ VIN_Byte0 : 0|8@1+ (1,0) [0|255] "" DME,EGS,CIC,Kombi
 SG_ VIN_Byte1 : 8|8@1+ (1,0) [0|255] "" DME,EGS,CIC,Kombi
 SG_ VIN_Byte2 : 16|8@1+ (1,0) [0|255] "" DME,EGS,CIC,Kombi
 SG_ VIN_Byte3 : 24|8@1+ (1,0) [0|255] "" DME,EGS,CIC,Kombi
 SG_ VIN_Byte4 : 32|8@1+ (1,0) [0|255] "" DME,EGS,CIC,Kombi
 SG_ VIN_Byte5 : 40|8@1+ (1,0) [0|255] "" DME,EGS,CIC,Kombi
 SG_ VIN_Byte6 : 48|8@1+ (1,0) [0|255] "" DME,EGS,CIC,Kombi

BO_ 897 EngineOilLevel: 2 DME
 SG_ OilLevel_MeasState : 0|8@1+ (1,0) [0|255] "" CIC,Kombi
 SG_ OilLevel_Status    : 8|8@1+ (1,0) [0|255] "" CIC,Kombi

BO_ 898 Electronic_engine_oil_dipstick_M: 8 DME

BO_ 899 Motor_data_2: 4 DME

BO_ 904 Vehicle_type: 8 CAS

BO_ 907 Status_battery: 8 DME

BO_ 910 Start_speed: 8 DME

BO_ 914 Status_System_AFS: 8 AFS

BO_ 916 RDA_request_data_storage: 8 Kombi

BO_ 917 Coding_power_management: 8 CAS

BO_ 920 Operation_chassis: 8 CCC

BO_ 921 Status_MDrive: 6 DME

BO_ 926 Operation_time_date: 8 CCC

BO_ 928 Vehicle_state: 8 Gate1

BO_ 931 Request_Remote_Services: 8 CCC

BO_ 937 Status_motor_control_CKM: 8 DME

BO_ 939 Status_Shiftlights_CKM: 8 Kombi

BO_ 940 RunOnTimeTerminal30: 2 Gate1

BO_ 944 Status_gear_reverse: 8 FRMFA
 SG_ ReverseGear_3B0 : 8|8@1+ (1,0) [0|255] "" PDC,CIC

BO_ 945 TransmissionData3: 6 DKG
 SG_ Checksum_0x3b1 : 0|8@1+ (1,0) [0|19] "" DME,Kombi,DSC
 SG_ Counter_0x3b1 : 8|4@1+ (1,0) [0|14] "" DME,Kombi,DSC

BO_ 947 PowerManagmentConsumptionControl: 6 DME

BO_ 948 PowerBatteryVoltage: 8 DME
 SG_ BatteryVoltage : 0|12@1+ (0.015,0) [0|65535] "V" Kombi,CIC

BO_ 949 Status_water_valve: 8 Gate1

BO_ 950 Position_window_lifter_FAT: 8 FRMFA
 SG_ WindowPosition : 0|8@1+ (1,0) [0|87] "" Kombi
 SG_ WindowMovement : 8|8@1+ (1,0) [0|255] "" Kombi
 SG_ WindowMotionFlags : 16|8@1+ (1,0) [0|255] "" Kombi

BO_ 951 Position_window_lifter_FATH: 8 Gate1
 SG_ WindowPosition : 0|8@1+ (1,0) [0|87] "" Kombi
 SG_ WindowMovement : 8|8@1+ (1,0) [0|255] "" Kombi
 SG_ WindowMotionFlags : 16|8@1+ (1,0) [0|255] "" Kombi

BO_ 952 Position_window_regulator_BFT: 8 FRMFA
 SG_ WindowPosition : 0|8@1+ (1,0) [0|87] "" Gate1
 SG_ WindowMovement : 8|8@1+ (1,0) [0|255] "" Gate1
 SG_ WindowMotionFlags : 16|8@1+ (1,0) [0|255] "" Gate1

BO_ 953 Position_window_regulator_BFTH: 8 Gate1
 SG_ WindowPosition : 0|8@1+ (1,0) [0|87] "" Gate1
 SG_ WindowMovement : 8|8@1+ (1,0) [0|255] "" Gate1
 SG_ WindowMotionFlags : 16|8@1+ (1,0) [0|255] "" Gate1

BO_ 954 Position_SHD: 8 FZD

BO_ 956 Position_window_lifter_security_vehicle: 8 XXX

BO_ 957 Status_consumer_shutdown: 8 FRMFA

BO_ 958 PowerRunningTime: 2 CAS

BO_ 959 Position_window_rear_window: 8 CTM

BO_ 960 Configuration_FAS: 8 SM_FA

BO_ 961 Configuration_BFS: 8 SM_BF

BO_ 964 Status_EDCK_CKM: 8 Gate1

BO_ 967 Access_radio: 8 RAD1

BO_ 968 Operation_push_button_radio: 8 RAD1

BO_ 972 NavGraph_3CC: 7 CCC_GW

BO_ 974 Radio_audio_control_interface_display: 8 ACI

BO_ 975 Acknowledgment_access_radio_audio_control_interface: 8 ACI

BO_ 979 Status_solar_sensor: 8 FZD

BO_ 980 Configuration_of_central_locking_CKM: 8 Kombi

BO_ 981 Status_central_locking_CKM: 8 CAS

BO_ 982 Configuration_DWA_CKM: 8 Kombi

BO_ 983 Status_DWA_CKM: 8 FZD

BO_ 984 Configuration_RLS_CKM: 8 Kombi

BO_ 985 Status_RLS_CKM: 8 FZD

BO_ 986 Configuration_of_memory_positions_CKM: 8 Kombi

BO_ 987 Status_memory_positions_CKM: 8 SM_FA

BO_ 988 Configuration_light_CKM: 8 Kombi

BO_ 989 Status_light_CKM: 8 FRMFA

BO_ 990 Configuration_Climate_CKM: 8 CCC

BO_ 991 Status_Klima_CKM: 8 IHKA

BO_ 994 Configuration_of_tailgate_CKM: 8 CCC

BO_ 995 Status_tailgate_CKM: 8 HKL

BO_ 996 Configuration_rear_view_camera_CKM: 8 CCC

BO_ 1007 EngineOBD_data: 3 DME

BO_ 1009 LightExtStatus_CKM_3F1: 1 LM

BO_ 1015 NavGraph_3F7: 8 CCC_GW

BO_ 1043 FRM_LampStatus_413: 8 FRM

BO_ 1045 FRM_LampStatus_415: 7 FRM
 SG_ InitCounter : 0|2@1+ (1,0) [0|3] "" Kombi,CIC

BO_ 1152 NetworkMgmt_KGM_480: 0 KGM

BO_ 1153 NetworkMgmt_ACSM_481: 0 ACSM

BO_ 1170 NetworkMgmt_DME_492: 0 DME1

BO_ 1175 NetworkMgmt_EKP_497: 0 EKP

BO_ 1176 NetworkMgmt_EGS_498: 0 EGS_MECH

BO_ 1193 NetworkMgmt_DSC_4A9: 0 DXC_RB

BO_ 1216 NetworkMgmt_CAS_4C0: 0 CAS

BO_ 1238 NetworkManagment_4D6: 8 XXX

BO_ 1246 NetworkMgmt_GWS_4DE: 0 GWS
 SG_ IgnOff : 12|1@0+ (1,0) [0|3] "" Diagnosetool_K_CAN_System

BO_ 1248 NetworkMgmt_Kombi_4E0: 0 Kombi

BO_ 1250 NetworkMgmt_CCC_4E2: 0 CCC_GW

BO_ 1255 NetworkMgmt_ZBE_4E7: 0 ZBE

BO_ 1266 NetworkMgmt_KBM_4F2: 0 KBM

BO_ 1267 NetworkMgmt_CID_4F3: 0 CID_C

BO_ 1272 NetworkMgmt_IHKA_4F8: 0 IHKA

BO_ 1408 Services_KGM_580: 8 KGM

BO_ 1409 Services_ACSM_581: 8 ACSM
 SG_ SeatbeltLightOn : 24|1@1+ (1,0) [0|1] "" Diagnosetool_K_CAN_System

BO_ 1426 Services_DME_592: 8 DME1

BO_ 1432 Services_EGS_598: 8 EGS_MECH

BO_ 1449 Services_DSC_5A9: 8 DXC_RB

BO_ 1472 Services_CAS_5C0: 8 CAS

BO_ 1494 Services_5D6: 8 XXX

BO_ 1504 Services_Kombi_5E0: 8 Kombi

BO_ 1506 ZBE_Button_5E2: 8 ZBE

BO_ 1511 Services_ZBE_5E7: 8 ZBE

BO_ 1522 Services_KBM_5F2: 8 KBM

BO_ 1528 Services_IHKA_5F8: 8 IHKA

BO_ 1544 PTCAN_RESP_608_DME: 8 DME
 SG_ ISOTP_PCI : 4|4@1+ (1,0) [0|15] "" Diagnosetool_PT_CAN
 SG_ ISOTP_DL : 0|4@1+ (1,0) [0|15] "" Diagnosetool_PT_CAN
 SG_ UDS_ServiceId : 8|8@1+ (1,0) [0|255] "" Diagnosetool_PT_CAN
 SG_ UDS_Payload : 16|48@1+ (1,0) [0|0] "" Diagnosetool_PT_CAN

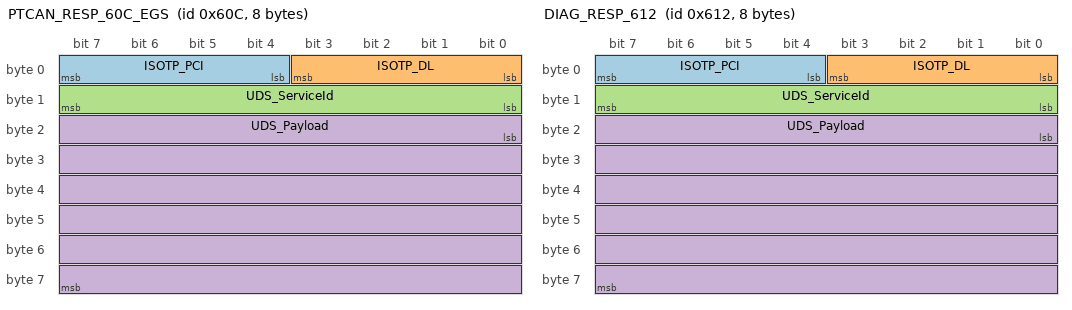
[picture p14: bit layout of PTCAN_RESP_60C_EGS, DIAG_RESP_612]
BO_ 1548 PTCAN_RESP_60C_EGS: 8 EGS
 SG_ ISOTP_PCI : 4|4@1+ (1,0) [0|15] "" Diagnosetool_PT_CAN
 SG_ ISOTP_DL : 0|4@1+ (1,0) [0|15] "" Diagnosetool_PT_CAN
 SG_ UDS_ServiceId : 8|8@1+ (1,0) [0|255] "" Diagnosetool_PT_CAN
 SG_ UDS_Payload : 16|48@1+ (1,0) [0|0] "" Diagnosetool_PT_CAN

BO_ 1554 DIAG_RESP_612: 8 DME
 SG_ ISOTP_PCI : 4|4@1+ (1,0) [0|15] "" DIA,Diagnosetool_K_CAN_System
 SG_ ISOTP_DL : 0|4@1+ (1,0) [0|15] "" DIA,Diagnosetool_K_CAN_System
 SG_ UDS_ServiceId : 8|8@1+ (1,0) [0|255] "" DIA,Diagnosetool_K_CAN_System
 SG_ UDS_Payload : 16|48@1+ (1,0) [0|0] "" DIA,Diagnosetool_K_CAN_System

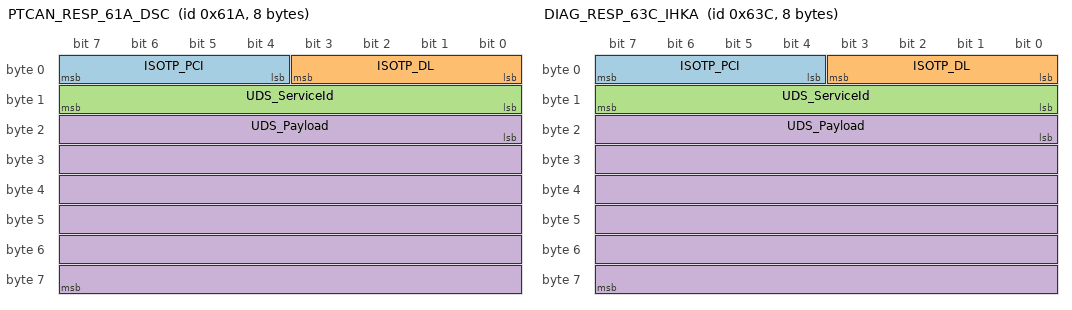
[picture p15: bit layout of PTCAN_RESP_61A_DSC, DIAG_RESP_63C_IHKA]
BO_ 1562 PTCAN_RESP_61A_DSC: 8 DSC
 SG_ ISOTP_PCI : 4|4@1+ (1,0) [0|15] "" Diagnosetool_PT_CAN
 SG_ ISOTP_DL : 0|4@1+ (1,0) [0|15] "" Diagnosetool_PT_CAN
 SG_ UDS_ServiceId : 8|8@1+ (1,0) [0|255] "" Diagnosetool_PT_CAN
 SG_ UDS_Payload : 16|48@1+ (1,0) [0|0] "" Diagnosetool_PT_CAN

BO_ 1577 Unknown_629: 8 XXX

BO_ 1596 DIAG_RESP_63C_IHKA: 8 IHKA
 SG_ ISOTP_PCI : 4|4@1+ (1,0) [0|15] "" DIA,Diagnosetool_K_CAN_System
 SG_ ISOTP_DL : 0|4@1+ (1,0) [0|15] "" DIA,Diagnosetool_K_CAN_System
 SG_ UDS_ServiceId : 8|8@1+ (1,0) [0|255] "" DIA,Diagnosetool_K_CAN_System
 SG_ UDS_Payload : 16|48@1+ (1,0) [0|0] "" DIA,Diagnosetool_K_CAN_System

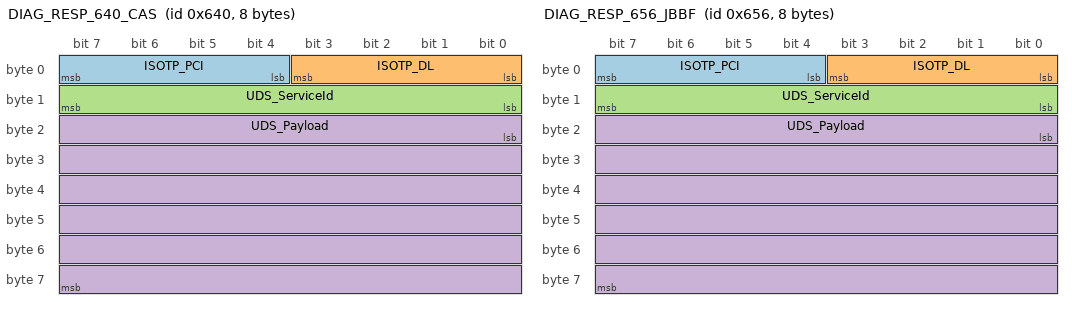
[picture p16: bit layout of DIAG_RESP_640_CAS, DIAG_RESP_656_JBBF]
BO_ 1600 DIAG_RESP_640_CAS: 8 CAS
 SG_ ISOTP_PCI : 4|4@1+ (1,0) [0|15] "" DIA,Diagnosetool_K_CAN_System
 SG_ ISOTP_DL : 0|4@1+ (1,0) [0|15] "" DIA,Diagnosetool_K_CAN_System
 SG_ UDS_ServiceId : 8|8@1+ (1,0) [0|255] "" DIA,Diagnosetool_K_CAN_System
 SG_ UDS_Payload : 16|48@1+ (1,0) [0|0] "" DIA,Diagnosetool_K_CAN_System

BO_ 1622 DIAG_RESP_656_JBBF: 8 Gate1
 SG_ ISOTP_PCI : 4|4@1+ (1,0) [0|15] "" DIA,Diagnosetool_K_CAN_System
 SG_ ISOTP_DL : 0|4@1+ (1,0) [0|15] "" DIA,Diagnosetool_K_CAN_System
 SG_ UDS_ServiceId : 8|8@1+ (1,0) [0|255] "" DIA,Diagnosetool_K_CAN_System
 SG_ UDS_Payload : 16|48@1+ (1,0) [0|0] "" DIA,Diagnosetool_K_CAN_System

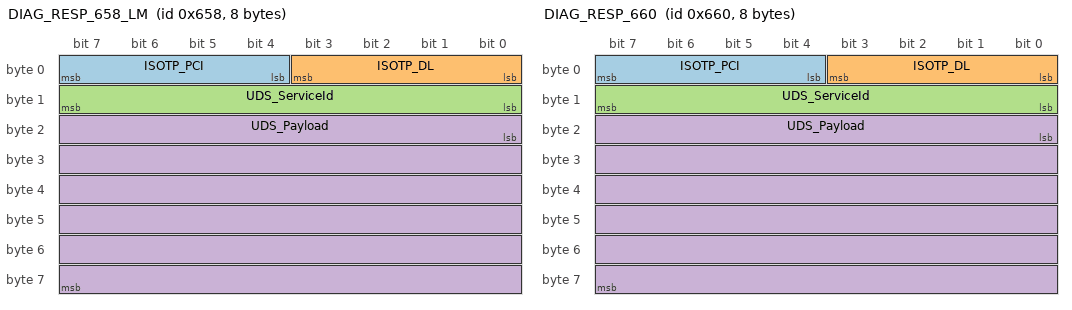
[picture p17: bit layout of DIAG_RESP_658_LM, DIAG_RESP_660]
BO_ 1624 DIAG_RESP_658_LM: 8 AFS
 SG_ ISOTP_PCI : 4|4@1+ (1,0) [0|15] "" DIA,Diagnosetool_K_CAN_System
 SG_ ISOTP_DL : 0|4@1+ (1,0) [0|15] "" DIA,Diagnosetool_K_CAN_System
 SG_ UDS_ServiceId : 8|8@1+ (1,0) [0|255] "" DIA,Diagnosetool_K_CAN_System
 SG_ UDS_Payload : 16|48@1+ (1,0) [0|0] "" DIA,Diagnosetool_K_CAN_System

BO_ 1632 DIAG_RESP_660: 8 Kombi
 SG_ ISOTP_PCI : 4|4@1+ (1,0) [0|15] "" DIA,Diagnosetool_K_CAN_System
 SG_ ISOTP_DL : 0|4@1+ (1,0) [0|15] "" DIA,Diagnosetool_K_CAN_System
 SG_ UDS_ServiceId : 8|8@1+ (1,0) [0|255] "" DIA,Diagnosetool_K_CAN_System
 SG_ UDS_Payload : 16|48@1+ (1,0) [0|0] "" DIA,Diagnosetool_K_CAN_System

BO_ 1640 DIAG_RESP_668_SZL: 8 SZL
 SG_ ISOTP_PCI : 4|4@1+ (1,0) [0|15] "" DIA,Diagnosetool_K_CAN_System
 SG_ ISOTP_DL : 0|4@1+ (1,0) [0|15] "" DIA,Diagnosetool_K_CAN_System
 SG_ UDS_ServiceId : 8|8@1+ (1,0) [0|255] "" DIA,Diagnosetool_K_CAN_System
 SG_ UDS_Payload : 16|48@1+ (1,0) [0|0] "" DIA,Diagnosetool_K_CAN_System

BO_ 1650 DIAG_RESP_672_FRM3: 8 FRM
 SG_ ISOTP_PCI : 4|4@1+ (1,0) [0|15] "" DIA,Diagnosetool_K_CAN_System
 SG_ ISOTP_DL : 0|4@1+ (1,0) [0|15] "" DIA,Diagnosetool_K_CAN_System
 SG_ UDS_ServiceId : 8|8@1+ (1,0) [0|255] "" DIA,Diagnosetool_K_CAN_System
 SG_ UDS_Payload : 16|48@1+ (1,0) [0|0] "" DIA,Diagnosetool_K_CAN_System

BO_ 1676 DIAG_RESP_68C_PDC: 8 PDC
 SG_ ISOTP_PCI : 4|4@1+ (1,0) [0|15] "" DIA,Diagnosetool_K_CAN_System
 SG_ ISOTP_DL : 0|4@1+ (1,0) [0|15] "" DIA,Diagnosetool_K_CAN_System
 SG_ UDS_ServiceId : 8|8@1+ (1,0) [0|255] "" DIA,Diagnosetool_K_CAN_System
 SG_ UDS_Payload : 16|48@1+ (1,0) [0|0] "" DIA,Diagnosetool_K_CAN_System

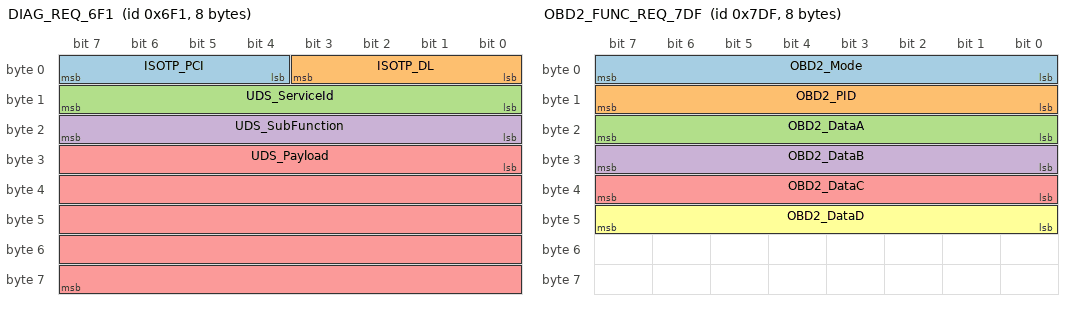
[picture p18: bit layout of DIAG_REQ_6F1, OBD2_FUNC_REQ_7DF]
BO_ 1777 DIAG_REQ_6F1: 8 DIA
 SG_ ISOTP_PCI : 4|4@1+ (1,0) [0|15] "" Vector__XXX
 SG_ ISOTP_DL : 0|4@1+ (1,0) [0|15] "" Vector__XXX
 SG_ UDS_ServiceId : 8|8@1+ (1,0) [0|255] "" Vector__XXX
 SG_ UDS_SubFunction : 16|8@1+ (1,0) [0|255] "" Vector__XXX
 SG_ UDS_Payload : 24|40@1+ (1,0) [0|0] "" Vector__XXX

BO_ 1987 Keyfob_7C3: 8 XXX

BO_ 2015 OBD2_FUNC_REQ_7DF: 8 DIA
 SG_ OBD2_Mode : 0|8@1+ (1,0) [0|255] "" Vector__XXX
 SG_ OBD2_PID : 8|8@1+ (1,0) [0|255] "" Vector__XXX
 SG_ OBD2_DataA : 16|8@1+ (1,0) [0|255] "" Vector__XXX
 SG_ OBD2_DataB : 24|8@1+ (1,0) [0|255] "" Vector__XXX
 SG_ OBD2_DataC : 32|8@1+ (1,0) [0|255] "" Vector__XXX
 SG_ OBD2_DataD : 40|8@1+ (1,0) [0|255] "" Vector__XXX

BO_ 2016 OBD2_PHYS_REQ_7E0_DME: 8 DIA
 SG_ OBD2_Mode : 0|8@1+ (1,0) [0|255] "" DME
 SG_ OBD2_PID : 8|8@1+ (1,0) [0|255] "" DME
 SG_ OBD2_DataA : 16|8@1+ (1,0) [0|255] "" DME
 SG_ OBD2_DataB : 24|8@1+ (1,0) [0|255] "" DME

BO_ 2017 OBD2_PHYS_REQ_7E1_EGS: 8 DIA
 SG_ OBD2_Mode : 0|8@1+ (1,0) [0|255] "" EGS
 SG_ OBD2_PID : 8|8@1+ (1,0) [0|255] "" EGS
 SG_ OBD2_DataA : 16|8@1+ (1,0) [0|255] "" EGS
 SG_ OBD2_DataB : 24|8@1+ (1,0) [0|255] "" EGS

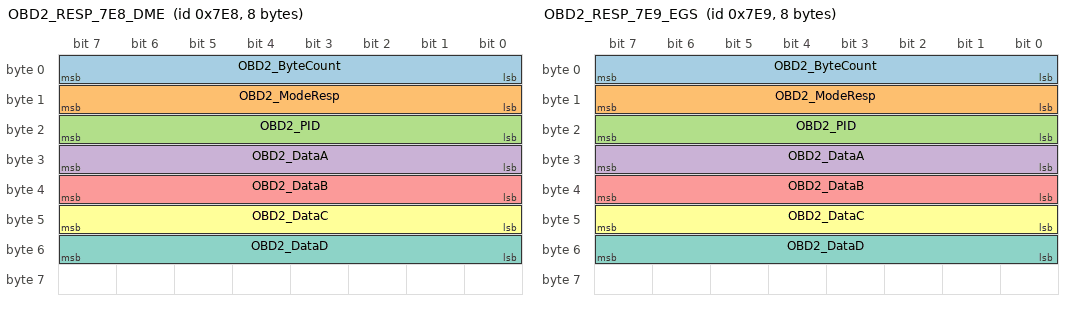
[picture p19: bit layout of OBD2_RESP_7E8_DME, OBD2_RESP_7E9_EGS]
BO_ 2024 OBD2_RESP_7E8_DME: 8 DME
 SG_ OBD2_ByteCount : 0|8@1+ (1,0) [0|7] "" DIA
 SG_ OBD2_ModeResp : 8|8@1+ (1,0) [0|255] "" DIA
 SG_ OBD2_PID : 16|8@1+ (1,0) [0|255] "" DIA
 SG_ OBD2_DataA : 24|8@1+ (1,0) [0|255] "" DIA
 SG_ OBD2_DataB : 32|8@1+ (1,0) [0|255] "" DIA
 SG_ OBD2_DataC : 40|8@1+ (1,0) [0|255] "" DIA
 SG_ OBD2_DataD : 48|8@1+ (1,0) [0|255] "" DIA

BO_ 2025 OBD2_RESP_7E9_EGS: 8 EGS
 SG_ OBD2_ByteCount : 0|8@1+ (1,0) [0|7] "" DIA
 SG_ OBD2_ModeResp : 8|8@1+ (1,0) [0|255] "" DIA
 SG_ OBD2_PID : 16|8@1+ (1,0) [0|255] "" DIA
 SG_ OBD2_DataA : 24|8@1+ (1,0) [0|255] "" DIA
 SG_ OBD2_DataB : 32|8@1+ (1,0) [0|255] "" DIA
 SG_ OBD2_DataC : 40|8@1+ (1,0) [0|255] "" DIA
 SG_ OBD2_DataD : 48|8@1+ (1,0) [0|255] "" DIA

CM_ SG_ 168 Counter_0xa8 "Counter TORQ_1";
CM_ SG_ 168 TORQ_AVL "Actual engine torque without inertia - combustion torque";
CM_ SG_ 168 TORQ_AVL_DMEE "Theoretical engine torque - without inertia and without shifting interventions";
CM_ SG_ 168 ST_SW_CLT "clutch switch status";
CM_ SG_ 168 ST_DMEA_SWO "status DME/ACC motronic switch-off";
CM_ SG_ 168 RCPT_ACC_SWO_SYS_DME "receipt_ACC_switch-off_system_DME";
CM_ SG_ 168 BrakePressed "Brake when driver presses the brake or hill hold";
CM_ BO_ 168 "0x0A8 (DME): Engine torque, brake and clutch status. TORQ_AVL (B2 signed, repeated in B4) is torque demand: ~0x02 at idle, +0x2E (~47) heavy acceleration, 0xFA–0xFD (~−3 to −6) during engine braking/overrun fuel cut. HIL-confirmed in 5min_run_for_testing.log 2026-03-26: highest values (0x27–0x2F) during sustained acceleration in 6th gear.";
CM_ BO_ 170 "0x0AA (DME): Throttle / accelerator pedal data";
CM_ SG_ 170 AcceleratorPedalPercentage "ToDo Factor to be adjusted";
CM_ SG_ 170 ThrottlelActive "Active in cruise control when engine braking";
CM_ SG_ 170 AcceleratorPedalPressed "Active only when driver actually presses the pedal";
CM_ BO_ 182 "Tranction control and dynamic cruise control torque requests (DynamicCruiseControlTorqueDemand)";
CM_ SG_ 181 TORQ_TAR_EGS "torque target (fast)";
CM_ SG_ 181 ST_OTMP_GRB "overtemperature gearbox status";
CM_ SG_ 181 ST_OBD_GRB "status OBD_error gearbox";
CM_ SG_ 181 ST_LIM_STORQ "starting torque limitation status";
CM_ SG_ 181 TORQ_DRAW_GRB "Torque converter - looks like fluid path torque before multiplication";
CM_ SG_ 181 TEMP_GRB "Gearbox/ATF oil temperature. Encoding: phys = raw - 40 (C). Unsigned 0-255, range -40 to +215C. ZF 6HP19 normal operating range 60-90C, alarm >130C. Matches OBD2 PID 0x6C (ATF temp) standard. Source: Raiso77 (confirmed on GM gearbox via OBD2, 2026-03-31). Previously wrong in DBC as signed @1- offset +40 — corrected to unsigned @1+ offset -40. Not confirmed on ZF 6HP19 from our HIL (0x0B5 absent from all bench logs — EGS→DME message, no EGS simulation on bench).";
CM_ SG_ 182 TORQ_TAR_DSC "torque target (fast)";
CM_ SG_ 182 TORQ_TAR_ADJR_POS_DSC "torque target (slow)";
CM_ BO_ 183 "ACC or LDM - active cruise control torque request";
CM_ SG_ 183 TORQ_TAR_ACC "torque target (fast)";
CM_ SG_ 183 TORQ_TAR_ADJR_POS_DSC "torque target (slow)";
CM_ BO_ 184 "0x0B8 (DKG): DCT torque request";
CM_ SG_ 184 TORQ_TAR_DKG "torque target (fast)";
CM_ SG_ 184 TORQ_TAR_ADJR_POS_DKG "torque target (slow)";
CM_ BO_ 191 "Sent by DSC or LDM (ACC option)";
CM_ SG_ 191 STATE_DI_PUC "FOLDYN_WMOM_PT_TAR: request_prevention_inertia-fuel-shutof";
CM_ SG_ 191 STATE_SP_DYN_WHEEL "state follow dynamic from FOLDYN_WMOM_PT_TAR";
CM_ SG_ 191 WMOM_PT_TAR "Wheel torque request";
CM_ SG_ 191 ST_DRASY_PT "powertrain driver assistance system status";
CM_ SG_ 191 WMOM_PT_ENBL "wheel torque request enabled";
CM_ SG_ 191 RQ_GSI_CLCTR_LN "request gear shift indicator";
CM_ BO_ 196 "0x0C4 (SZL): Steering wheel angle";
CM_ SG_ 196 SteeringPosition "Steering wheel position in degrees";
CM_ SG_ 196 SteeringSpeed "Steering wheel rotational rate (deg/s)";
CM_ BO_ 200 "0x0C8 (SZL): Steering wheel angle slow rate";
CM_ SG_ 200 SteeringPosition "Steering wheel position in degrees";
CM_ SG_ 200 SteeringSpeed "Steering wheel rotational rate (deg/s)";
CM_ BO_ 206 "0x0CE (DSC): Wheel speed pulse counters — 4 wheels, 16-bit little-endian pairs: FL=B1:B0, FR=B3:B2, RL=B5:B4, RR=B7:B6. IMPORTANT: these are ABS ring pulse COUNTS per 100ms frame, NOT direct km/h. Frame is all-zeros when engine is off. At idle standstill (engine running): ~334–342 counts (vibration noise floor). At peak observed speed (~55–60 km/h city): ~903–913 counts. Rough formula: (raw_16LE − 338) × 0.1 ≈ km/h — offset and scale need one confirmed km/h calibration point to pin exactly. DBC signal factor 0.0625 is UNCONFIRMED — do not use until validated. Was all-zeros in all previous static/idle HIL logs; first confirmed active in 5min_run_for_testing.log 2026-03-26.";
CM_ BO_ 209 "0x0D1 (DME): Accelerometer data";
CM_ BO_ 215 "0x0D7 (ACSM): Alive counter security";
CM_ BO_ 226 "0x0E2 (Gate1): Door status — FR (Beifahrertür vorne, BFT, passenger front-right). B3=DoorOpenState: 0xFC=closed, 0xFD=open. B0=LockState: 0x81=unlocked, 0x82=locked, 0x83=armed (increments on ignition/session transition). B1=0xFF constant. B2=0xE7 constant. B4-B7=0xFF constant. B3=0xFD CONFIRMED: HIL-3 2026-03-24 at t=2748881ms (FR door opened second in FL→FR→RL→RR sequential 4-door test, held ~10s, event-driven burst of 6 groups). Door ID mapping confirmed by sequential hold test: FL=0x0EA, FR=0x0E2, RL=0x0EE, RR=0x0E6. Source: HIL session 2026-03-24 (10minutes_run_Wheel_doors_tests.log)";
CM_ BO_ 230 "0x0E6 (Gate1): Door status — RR (Beifahrertür hinten, BFTH, passenger rear-right). Same byte layout as 0x0E2/0x0EA/0x0EE: B0=LockState (0x81=unlocked, 0x82=locked, 0x83=armed), B3=DoorOpenState (0xFC=closed, 0xFD=open), B1=0xFF, B2=0xE7 constant. B3=0xFD CONFIRMED: HIL-3 2026-03-24 at t=2778797ms (RR door opened fourth in FL→FR→RL→RR sequential 4-door test, held ~10s, event-driven burst of 2 groups). Door ID mapping confirmed by sequential hold test: FL=0x0EA, FR=0x0E2, RL=0x0EE, RR=0x0E6. Source: HIL session 2026-03-24 (10minutes_run_Wheel_doors_tests.log)";
CM_ BO_ 234 "0x0EA (Gate1): Door status — FL driver front (Fahrertür vorne, FAT). B0=LockState: 0x81=unlocked, 0x82=locked, 0x83=armed. B3=DoorOpenState: 0xFC=closed, 0xFD=open. B1=0xFF, B2=0xE7 constant. B3=0xFD CONFIRMED twice: (1) HIL 2026-03-23: B3=0xFD when driver entered car. (2) keyless-restart log 2026-03-24: B3=0xFD at t+26.4s when driver exited running keyless car (held ~5s, then 0xFC). Simultaneously with 0x130 B0 transition to 0x05 (security-alert state). This is the driver door — highest event density, most reliable for door-open detection. B0 lock state changes in real-time: 0x81→0x82 at keyfob lock (simultaneous with 0x2A0 command frame). Source: HIL 2026-03-23 + keyless-restart 2026-03-24";
CM_ BO_ 238 "0x0EE (Gate1): Door status — RL driver rear (Fahrertür hinten, FATH). Same byte layout as 0x0E2/0x0E6/0x0EA: B0=LockState (0x81=unlocked, 0x82=locked, 0x83=armed), B3=DoorOpenState (0xFC=closed, 0xFD=open). B3=0xFD CONFIRMED: captured at t=2765496ms in 10minutes_run_Wheel_doors_tests.log 2026-03-24 (door held open ~10s, B0=0x81 unlocked). This is the only door frame with open state directly captured in HIL logs to date — confirms the 0xFC/0xFD decode is correct. B1=0xFF, B2=0xE7 constant. Source: HIL 2026-03-23 + HIL doors log 2026-03-24";
CM_ BO_ 242 "0x0F2 (Gate1): Central locking status HK (boot/trunk area)";
CM_ BO_ 250 "0x0FA (FRMFA — Footwell Module): All 4 window command frame. 3 bytes: B0=front commands, B1=rear commands, B2=0xFF constant. Idle: 80 00 FF. B0/B1 bit map (base 0x80): bit0=DrvClose(hold), bit1=DrvAutoClose(one-touch), bit2=DrvOpen(hold), bit3=PasClose(hold), bit4=PasAutoClose(one-touch), bit5=PasOpen(hold). Confirmed from Windows_cycle.log + injection tests 2026-04-06: front-both-autoclose=A4 00 FF, rear-both-autoclose=80 24 FF. INJECTION NOTE: sending B0+B1 combined (A4 24 FF) closes only rear — likely B0 rejected by FRM when B1 non-zero (FRM owns B0, JBE owns B1). Workaround: inject A4 00 FF then 80 24 FF sequentially (~500ms each). PARTIAL CONFIRM 2026-04-07: front driver autoclose (bit1 in B0) does NOT work via injection — front passenger and both rears confirmed. Front driver close mechanism unclear.";
CM_ BO_ 251 "0x0FB (Gate1): Window lifter control front-right";
CM_ BO_ 304 "0x130 (CAS — Car Access System): Ignition/key/terminal status frame at ~10 Hz. Confirmed decode (HIL keyfobless_restart_lock.log 2026-03-24): B0=IgnitionMode: 0x45=KL15_RUN (normal running), 0x55=CRANKING/starting (engineStarting), 0x41=ACCESSORY (KL15 on, engine off), 0x40=transitional/shutdown (ignition winding down, keeps previous state in decoder), 0x05=SECURITY_ALERT (engine running without authorised key — persists when car is locked externally with engine on). B1 encodes key presence and door/security context: 0x40=key_present_normal (bit6=1), 0x1A=key_absent_door_closed, 0x0D=key_absent_door_open_or_security_event. B2/B3=variable (clutch nibble in B2 hi-nibble: 0xA=unknown, decodes unchanged). KEYLESS RESTART CONFIRMED: B0=0x55 + B1=0x1A observed when engine cranks without physical key — CAS allows restart within security window after key removal. CRANK TIMING (N47D20O1): B0=0x55 fires → 0x21A engine_running bit in 13ms → RPM measurable in 264ms → B0 settles to 0x45 in ~800ms total. LOCKED-RUNNING STATE: after driver exits and keyfob-locks running car, B0 stays at 0x05, B1=0x0D indefinitely — distinct from all normal run states. Source: HIL sessions 2026-03-23 + keyless-restart 2026-03-24";
CM_ SG_ 304 IgnitionOff "Active when engine off (KL15 de-energised)";
CM_ BO_ 309 "0x135 (ACSM): Crash disconnect control";
CM_ BO_ 370 "0x172 (CCC): Acknowledgment/fault-count notification. FAULT-ONLY — absent in normal startup. Companion to 0x338 (same counter and fault-count structure, both appear at +13s). DLC=5. Initialises as FF FF FF 0F F1, then transitions to: B0=rolling counter (bit 0 toggles: 0x78/0x79). B2=active fault count (0x02→0x01 as per 0x338). B3=0x60. B4=0xF0. Source: HIL 2026-05-03 low-beam fault log.";
CM_ BO_ 373 "0x175 (DME): Engine RPM. B0=rolling counter (0x00–0x0E, 15-step). B2=RPM_HIGH byte: formula B2 × 40 = RPM (resolution ±40 RPM). Full 16-bit (B2<<8|B1) encodes finer precision. HIL calibration points from 5min_run_for_testing.log 2026-03-26: B2=0x15(21)→~840 RPM (N47 diesel idle), B2=0x18(24)→~960 RPM (light cruise), B2=0x2A(42)→~1680 RPM (acceleration), B2=0x38(56)→~2240 RPM (hard acceleration peak), B2=0x0C(12)→~480 RPM (overrun/fuel-cut). Existing DBC signals (CruiseControlSetpointSpeed etc.) are from loopybunny — RPM signal not previously mapped. Source: HIL 2026-03-26.";
CM_ BO_ 402 "0x192: Gear selector / transmission selector switch operation. Sender: SZL_LWS (Schaltzentrum Lenkrad / Lenkwinkelsensor — Steering Column Switch Centre with integrated Steering Angle Sensor, node 0x02). Also referred to as GearSelectorSwitch_1 in some DBC files. This is the tiptronic/gear-lever operation message from the column stalk. Source: MorGuux E90 K-CAN gist (entry: 402,0x192,Transmission Selector Switch Operation [16],SZL_LWS)";
CM_ BO_ 403 "0x193 (DSC): Dynamic cruise control status";
CM_ SG_ 403 CruiseControlSetpointSpeed "Speed target - unit depends on locale";
CM_ SG_ 404 Counter_0x194 "Message is sent at higher rate when cruise stalk is pressed";
CM_ SG_ 404 plus1 "Appears when +1mph/kph stalk is depressed";
CM_ SG_ 404 minus1 "Appears when -1mph/kph stalk is depressed";
CM_ SG_ 404 cancel "Appears when cancel stalk (up or down) is depressed";
CM_ SG_ 404 resume "It appears when resume stalk button is depressed";
CM_ SG_ 404 cancel_lever_up "Appears when cancel stalk (up) is depressed";
CM_ BO_ 414 "0x19E (DSC): DSC status K-CAN";
CM_ SG_ 414 DSC_full_off "0x4 enabling, 0xA enabled. TBD";
CM_ BO_ 418 "0x1A2 (EGS): Transmission data 2";
CM_ SG_ 408 ShifterPosition "0001 = N|R, 0010 = R, 0011 = N|D, 0100 = D, 0101 = -1, 0110 = +1, 0111 = ManualMode, 1000 = inBetween,";
CM_ SG_ 408 param1 "can not be 0x03. Always 0 in 135i.";
CM_ SG_ 408 ParkButtonFirst "0x1 = pressed";
CM_ SG_ 408 ParkButtonSecond "Redundant buton. 0x1 = pressed;";
CM_ SG_ 408 SideButton "0x1 = pressed;";
CM_ SG_ 408 SideButtonXOR11 "Complement value";
CM_ SG_ 408 param5 "Always 0 in 135i.";
CM_ SG_ 408 SportButtonPressed "0x1 = pressed;";
CM_ SG_ 408 M3_button "M3 POWER (?)";
CM_ BO_ 422 "0x1A6 (DSC): Speed pulse counters for instrument cluster and time counter. SpeedCounter1/2/3 are duplicated speed pulse counters; TimeCounter increments by 100 every 50ms. Source: loopybunny.co.uk/CarPC";
CM_ BO_ 436 "0x1B4 (CCC): Instrument cluster status — handbrake";
CM_ BO_ 437 "0x1B5 (IHKA — Automatic Climate Control): Heat flow climate";
CM_ BO_ 438 "0x1B6 (DME): Heat flow engine";
CM_ BO_ 450 "0x1C2 (PDC): Front and rear PDC sensor distances. RL/FL is furthest left, RR/FR is furthest right. Mid = inner sensors.";
CM_ BO_ 464 "0x1D0 (DME): Engine data — coolant temp, oil temp (petrol/some diesel), idle target RPM. TEMP_EOI (B1) returns 0xFF on N47 diesel (signal not available — N47 does not expose oil temp via K-CAN gateway; OBD-II PID 0x5C or PT-CAN required). TEMP_EOI is valid on petrol engines (N43, N52, N54, etc.) using same raw-48=C formula as TEMP_ENG.";
CM_ SG_ 464 TEMP_EOI "Engine oil temperature. Formula: raw - 48 = degC. Valid on petrol engines (N43, N52, N54, etc.). NOT AVAILABLE on N47 diesel: returns 0xFF permanently after engine start (= 207 degC with formula — discard, signal absent). Use OBD-II PID 0x5C or PT-CAN for oil temp on N47. Validated HIL 2026-03-24: 10minutes_run_temp_24_16_28_24.log shows B1=0x30 briefly at cold start, 0x42 for ~30s, then 0xFF for remainder of run.";
CM_ SG_ 464 TEMP_ENG "Coolant temperature. Formula: raw - 48 = degC. Confirmed on N47 diesel: 0x3E=14C cold start (ambient), rises to 0x62=50C after 10 min, 0x88=88C at operating temp. Source: HIL 2026-03-24 temp log.";
CM_ BO_ 772 "0x304 (EGS): Current drive gear / selector state. B0=GearDisplay. ZF6HP19 6-speed automatic. Selector states (confirmed): 0xE3=Park, 0xC2=Reverse, 0xD1=Neutral, 0xC3=P->R transient (~320ms), 0xE1=R->P transient (1 frame, seen between C1 and E3 during R->Park at 0 km/h). B1=0xFF constant. Drive gear encoding CONFIRMED by speed-correlation HIL 2026-03-28 (mlog1, mlog2 = manual/Sport mode; dlog1 = Drive mode — encoding identical in both): 0xC5=1st (0 km/h creep), 0xC6=2nd (0-36 km/h), 0xC7=3rd (0-66 km/h), 0xC8=4th (10-78 km/h), 0xC9=5th (47-56 km/h), 0xCA=6th (72.9-94.8 km/h, avg 83.7 km/h, CONFIRMED 2026-03-29 idrive-can-capture-20260329-143516.log). 0xC1=1st in sport/stall state (always 0 km/h, appears at stops and parking; may indicate TC stall or manual 1st selection — distinct from C5 but same physical gear). Encoding is the same in automatic Drive mode and manual Sport/M mode — no difference observed. Paddle shifts are non-CAN (EGS-direct hardwired). Standing manual shift test (m1-m6_shift.log 2026-03-29): EGS only permits C5(M1) and C6(M2) from standstill — M3-M6 silently rejected (transmission protection). Source: mlog1/mlog2/dlog1 2026-03-28 + city_run 2026-03-27 + driving/shift logs 2026-03-29 HIL captures.";
CM_ BO_ 466 "0x1D2 (EGS): Transmission display data. ShiftLeverPosition HIL-validated: 1=P, 2=R, 4=N, 8=D. ShiftLeverMode (B4 bits 0-1): 0=Drive/Normal (B4=0xF0), 2=Sport/Manual (B4=0xF2). GearAct (B1 high nibble, bits 12-15) CONFIRMED HIL 2026-03-29: raw 5=1st, 6=2nd, 7=3rd, 8=4th, 9=5th, A=6th (formula raw-4=gear). Raw 0 = signal not populated (Drive mode only). GearAct ONLY active in Sport/Manual mode (B4=0xF2). Represents COMMANDED/REQUESTED gear (leads 0x304 by ~100-200ms; in standing m1-m6 test GearAct reached 6 while 0x304 stayed at C6 due to EGS protection). 0x304 Status_Gang = ENGAGED gear. Source: gearbox_modes, mlog1, mlog2, m1-m6_shift.log, city run 2026-03-27 HIL captures; GearAct confirmed 2026-03-29. --- Raiso77 notes (unconfirmed, 2026-03-31): B1/GearAct only populated on XHP or Alpina gearbox firmware; standard GM software does not use B1 in Drive mode (sends 0x0C = raw 0 = not populated) — consistent with our HIL observations. B5 (xFF signal): M3 DCT-specific mode byte only; always 0xFF on ZF 6HP19 — CONFIRMED in all HIL logs. B2: always 0xFF on ZF 6HP19; M3 DCT sends 0x9F — CONFIRMED (our logs: B2 always FF). B5 DCT values (Raiso77, M3 DCT only): 0x52=Drive(?), 0x51-0x55=shifted gears, 0x55=high gear; not applicable to ZF 6HP19.";
CM_ SG_ 416 LongAcc "Longitudinal acceleration";
CM_ SG_ 416 LatlAcc "Lateral acceleration";
CM_ SG_ 466 GearAct "EGS commanded/requested gear. Only valid in Sport/Manual mode (ShiftLeverMode=2, B4=0xF2). Raw 5-10 = gears 1-6 (formula raw-4). Raw 0 = not available (Drive mode). All 6 gears confirmed HIL 2026-03-29. Raiso77: standard GM firmware (ZF 6HP19) only uses B1 in Manual/Tip mode; XHP/Alpina firmware may populate in all modes (unconfirmed on our bench — bench runs stock GM firmware).";
CM_ SG_ 466 SportButtonState "Only selected powertrains. Makes throttle, overboost, suspension, steering, shiftpoints more aggressive. NOTE: on N47 diesel E90 without a physical Sport/S button this bit is structurally always 1 — B3 low nibble is permanently 0xC (bits 2-3 always set). Either EGS hardcodes sport-shift profile as default for this powertrain, or bits 2-3 are XOR/framing bits misidentified as a signal. Not meaningful as a toggle on no-sport-button variants. Confirmed across all HIL logs 2026-03-29: bit2=1 in every frame.";
CM_ SG_ 466 ShiftLeverMode "Gear selector mode. 0=Drive/Normal (B4=0xF0), 2=Sport/Manual (B4=0xF2). Dashboard shows D1-D6 in Normal, S1-S6 in Sport, M1-M6 in Manual. Confirmed HIL 2026-03-29.";
CM_ SG_ 466 xFF "B5 — M3 DCT-specific mode byte (Raiso77, 2026-03-31). Always 0xFF on ZF 6HP19 non-DCT — confirmed across all HIL logs. On M3 DCT: 0x52=Drive(?), 0x51-0x55=gear positions, 0x55=high. Not applicable to E90 ZF 6HP19.";
CM_ BO_ 470 "0x1D6 (SZL): Steering wheel MFL buttons";
CM_ BO_ 472 "0x1D8 (CCC): AC air distribution front";
CM_ BO_ 483 "0x1E3 (FZD): Interior light push-button";
CM_ BO_ 502 "0x1F6 (FRM — Footwell Module): Turn signal switch";
CM_ SG_ 502 HoldActivated "Spikes down if blinker cleared with timeout or turn. Stays off if blinker cleared with stalk";
CM_ SG_ 502 LeftTurn "Indicates left blinker or when steering returning left clears right blinker";
CM_ SG_ 502 RightTurn "Indicates right blinker or when steering returning right clears left blinker";
CM_ SG_ 502 TurnSignalActive "Turn signal on or transitioning";
CM_ SG_ 502 TurnSignalIdle "Turn signal off";
CM_ BO_ 514 "0x202 (FRM — Footwell Module): Dimming status";
CM_ BO_ 517 "0x205 (Kombi): Acoustic gong request. FAULT-ONLY — absent in normal startup. Fires at +13s coinciding with 0x338/0x172 fault notification. B0 bit 0 (GongCounter) toggles 0xF1→0xF0 across 3 rapid frames — event-driven toggle rather than a periodic heartbeat. Correlates with the audible warning gong on low-beam fault detection. Source: HIL 2026-05-03 low-beam fault log.";
CM_ BO_ 538 "0x21A (FRM — Footwell Module): Lighting and engine-running status. CORRECTION (keyless-restart log 2026-03-24): B0 bit7 is NOT KL15_Active — it is BRAKE_LIGHTS (brake pedal pressed). Evidence: bit7 clears to 0 immediately after start while engine is still running and KL15 is active (driver lifts foot off brake). The earlier correlation with ignition events was because diesel start requires brake pedal held, so brake-on and KL15-on events coincide. B0 bit0: reflects engine running state (1=engine running) but also correlates with dipped-beam (see full lighting decode). B0 bit2=SideLights. Confirmed B0 patterns: 0x04=sidelights_only (engine off, no brake), 0x84=brake+sidelights (brake pressed, engine off — restart prep), 0x85=brake+sidelights+engine_flag (cranking/just_started), 0x05=sidelights+engine_running_no_brake (normal driving), 0x05=also seen post-lock with engine on. B1=0x12 constant when KL15 active (from HIL-2). B2=0xF7 constant. [PARTIAL] Loopybunny exterior light decode (unconfirmed for this car): B0 lo-nibble: 0=all off, 4=sidelights/auto, 5=dip, 7=main. B1: 0=off, 1=reverse/tail, 16=interior, 18=interior+exterior. Source: loopybunny.co.uk/CarPC + HIL 2026-03-23 + keyless-restart 2026-03-24";
CM_ BO_ 550 "0x226 (FZD): Rain sensor and automatic wiper speed. B0=WiperActivity (0x00=off, 0x55=interval/active wiper mode set by rain sensor). B1=0xFE constant. B2=0xFF constant. B3=RainIntensity (0x00=no rain, 0x4F=rain detected — rises before wiper activates). B4=0xF3 constant. Source: 5ninutes_Full_Run_Cycle.log HIL capture (5 state changes observed with AUTO wiper in rain)";
CM_ BO_ 578 "0x242 (IHKA — Automatic Climate Control): Climate front status. B0 encodes recirc and special mode flags: bit0=always set, bit2=MaxACMode (0x05), bit4=RecircAuto (0x11), bit5=RecircManual (0x21). B1=0xF1 (0xF5 observed during defrost). B2 bit0=AC_Compressor_578 flag (0xFD=on, 0xFC=off). B3-B4=0xFF constant. Source: clima_modes_bottom_up.log HIL capture";
CM_ BO_ 582 "0x246 (IHKA — Automatic Climate Control): Climate setpoint and AC status. B0=0x3F constant (purpose unknown). B1=0xF3 constant (purpose unknown). B2=TEMPERATURE SETPOINT (DBC signal ClimaTempSetpoint is CORRECT): formula raw*0.5+2.5 degC, range 0x1B-0x33 (16.0-28.0 degC). Validated at three setpoints in dedicated HIL capture 10minutes_run_temp_24_16_28_24.log 2026-03-24: 0x2B=24.0C, 0x1B=16.0C, 0x33=28.0C — all confirmed. Values 0x00=LO, 0x01-0x1A=below scale, 0x34+=HI (observed up to 0x3A when dial turned past maximum). B2=0x00 with AC-off seen at start/end of session (LO/AC-off state). NOTE: previous CM_ (HIL 2026-03-23) incorrectly identified B2 as a rolling counter — that analysis was from sessions with static setpoint and the apparent increment was coincidental. The original DBC signal name ClimaTempSetpoint was correct all along. B3=AC_Compressor flag: 0xFC=off, 0xFD=on (HIL-confirmed across multiple sessions). Source: 10minutes_run.log 2026-03-22 + HIL 2026-03-23 + HIL temp log 2026-03-24";
CM_ BO_ 678 "0x2A6 (SZL): Wiper mode switch from steering column. WiperSpeedMode nibble: 0=off, 1=interval_1, 2=interval_2, 3=slow. WiperAutoActive bit4: 0=off, 1=AUTO. B1=0xF9 constant. Source: wipers.log HIL capture";
CM_ BO_ 690 "0x2B2 (DSC): Wheel pressure (TPMS)";
CM_ SG_ 691 Deceleration "Filtered deceleration. Opposite to AccY signal";
CM_ BO_ 691 "0x2B3 (DSC): Acceleration data";
CM_ BO_ 704 "0x2C0 (Kombi): LCD lighting / rear window heater status. B0 lo-nibble: 0x1F=normal, 0x3F=at startup (settling). B1: 0x00=normal, 0x81=rear-window-heater-active [HYPOTHESIS — HIL 2026-03-23: B1 changed 0x00→0x81 at t=327s during rear window heater test, stayed 0x81 until ignition-off — single session, needs confirmation with explicit on/off cycle]. B2=0x01 constant. Source: HIL 2026-03-23";
CM_ BO_ 758 "0x2F6 (FRM — Footwell Module): FZD interior ceiling light aggregate state. B0=FZD_InteriorState: 0x00=all_off, 0x01=courtesy_fade (single lamp, door just closed), 0x44=rear_on, 0x54=front_rear_on, 0x55=all_on_entry (door open / car entry). B1: 0xF5=initial/entry, 0xF0=running. Individual lamp bits unresolved. Source: FZD_Lights_right_to_Left_front_back.log + 5ninutes_Full_Run_Cycle.log HIL capture";
CM_ BO_ 760 "0x2F8 (Kombi): System date and time";
CM_ SG_ 760 DateM "Top 4 bits only, lower nibble is always 0xF. eg: Jan=0x1F, May=0x5F, Dec=0xCF";
CM_ BO_ 762 "0x2FA (ACSM): Seat belt and occupancy status. B0=driver status byte, B1=passenger status byte. CONFIRMED payloads 2026-04-07: FC=unlatched/unoccupied, FD=occupied. B1: 90=passenger unlatched, 91=passenger latched. Full confirmed states: FC 90=all belts unlatched, FD 91=both latched (driver+passenger). B2-B4=0xFF (unused/constant). Event-triggered, ~5s periodic during KL15-on. Source: HIL 2026-03-23 + confirmed 2026-04-07.";
CM_ BO_ 764 "0x2FC (CAS): Lock/latch status — unusual behaviour observed 2026-04-07. Always shows driver door correctly. Passenger front (FR): responds to central lock but not reliably. Rear doors: respond to central lock command but NOT to manual individual door open/close — only update on central lock operation. Behaviour suggests this frame tracks LATCH state (locked/unlocked by CAS) rather than physical door open/close. Physical door open status is in 0x0E2/0x0E6/0x0EA/0x0EE. Byte 0 bitmask (loopybunny): b0=driver, b2=passenger, b4=rear-driver, b6=rear-passenger. Byte 2 bitmask: b0=boot, b2=bonnet. Signal decode unconfirmed — needs dedicated per-door latch test. Source: loopybunny.co.uk/CarPC + HIL observation 2026-04-07.";
CM_ BO_ 784 "0x310 (Kombi): Ambient temperature and relative time";
CM_ BO_ 790 "0x316 (Gate1): DTC push-button. NOTE: single frame FC FF appears only at +74ms in lamp-fault startup logs and is absent in normal startup — may carry an early FRM/body status bit that differs when a lamp fault is present at ignition-on. Source: HIL 2026-05-03 low-beam fault comparison.";
CM_ SG_ 790 DTC_pressed "Traction control off. Message transmitted when pressed. Few presses may be required followed by off.";
CM_ SG_ 790 setMe_0x3FFF "All ones";
CM_ BO_ 797 "0x31D (DSC): Tire pressure status";
CM_ BO_ 814 "0x32E (IHKA — Automatic Climate Control): Climate internal control info. B0=LightSensor (dash dimming, 0-16). B3=IRTempSensor (interior cabin IR temp, formula raw*0.1+6=degC): HIL-observed 15.0C at cold start (14C ambient) rising to 16.5C after 10 min, 21.0C with cabin warmed by heater — physically consistent, best available interior temp signal on K-CAN. Formula and byte confirmed from loopybunny source + HIL 2026-03-24 cross-validation. B4=SolarSensor (0-255, raw lux proxy). NOTE: prior CM_ incorrectly cited this as 0x328 — correct hex ID is 0x32E. Source: loopybunny.co.uk/CarPC + HIL 2026-03-24";
CM_ BO_ 816 "0x330 (Kombi): Range / mileage (odometer)";
CM_ BO_ 821 "0x335 (EKP): Electric fuel pump status";
CM_ BO_ 823 "0x337 (DME): Fuel control status";
CM_ BO_ 824 "0x338 (Kombi): Check Control Message active fault notification. FAULT-ONLY — absent in normal startup, appears only when a lamp fault is detected. ~3 s period. B0: rolling counter (bit 0 toggles: 0x78/0x79). B2: active fault count (0x02=two faults e.g. left+right low beam, decrements to 0x01 as faults are acknowledged). B3=0xF0. B5-B7=0xFE (padding/unused). Timing: first frame at +13s, continues while fault active. Companion to 0x172 (same counter/fault-count structure). Source: HIL 2026-05-03 low-beam fault log.";
CM_ BO_ 841 "0x349 (Gate1): Raw fuel level sensor data (left and right tank floats)";
CM_ BO_ 842 "0x34A (CCC/MK4 nav): GPS Latitude (B0-B3) and Longitude (B4-B7). Both 32-bit signed Intel LE. Scale factor 1/2^23 * (180/pi) = ~8.382e-8 deg/LSB (BMW CCC/MK4 standard radian-based encoding). Confirmed format from CCC/MK4 documentation. Source: confirmed BMW CCC/MK4 format 2026-04-07.";
CM_ BO_ 847 "0x34F (Gate1): Handbrake lever contact. B0 bit0=Handbrake_pushed_down (1=lever down/released), B0 bit1=Handbrake_pulled_up (1=lever up/engaged). Exactly one bit active at a time. 0xFE=engaged, 0xFD=released. Validated across all HIL sessions: stationary sessions=0xFE, driving sessions=0xFD. Source: 5ninutes_Full_Run_Cycle.log HIL capture";
CM_ BO_ 870 "0x366 (Kombi): External temperature and remaining fuel range. B0=ExternalTemp unsigned (factor=0.5, offset=-41 degC): formula raw*0.5-41. Validated: raw 0x6B=107 → 12.5C confirmed against dashboard at 12.5C ambient. B1-B2=FuelRange (miles). Source: STATIC-01 validation 2026-03-21";
CM_ BO_ 884 "0x374 (DSC): Wheel tolerance adjustment";
CM_ BO_ 896 "0x380 (CAS): Chassis / VIN number — bytes 0-6 are ASCII characters of VIN digits. Source: loopybunny.co.uk/CarPC";
CM_ BO_ 897 "0x381 (DDE/DME→CIC/Kombi): Engine oil level response. Byte0=measurement state (sent on CIC request), Byte1=general status. Source: Raiso77. Not observed in HIL logs — message only transmitted when CIC requests oil level check.";
CM_ SG_ 897 OilLevel_MeasState "Oil level measurement state / value code (Byte0). Response to CIC oil-level request.";
CM_ SG_ 897 OilLevel_Status "Oil level general status (Byte1).";
VAL_ 897 OilLevel_MeasState 18 "Level below MIN" 37 "Level at MIN" 56 "Level between MIN and OK" 83 "Level OK" 105 "Level between OK and MAX" 133 "Level at MAX" 149 "Overcrowded / overfilled" 120 "No measurement possible" 121 "Measurement in progress" 122 "Oil level check OK" 123 "Measurement OK" 124 "Ignition OFF, no measurement possible" 125 "Oil level OK, precise measurement in progress" 126 "Oil level OK" 127 "Measurement in progress (alt)" 128 "Accurate measurement in progress (~1 min)" 255 "Signal invalid";
VAL_ 897 OilLevel_Status 240 "All OK" 241 "Overfilled" 242 "Refill 1.0 L" 244 "Service required" 255 "Signal invalid";
CM_ BO_ 940 "0x3AC (Gate1): Terminal 30 run-on time";
CM_ BO_ 944 "0x3B0 (FRM — Footwell Module): Reverse gear status. Byte 1: 0xFD=not in reverse, 0xFE=in reverse. Source: loopybunny.co.uk/CarPC";
CM_ BO_ 945 "0x3B1 (DKG): Transmission data 3";
CM_ BO_ 947 "0x3B3 (DME): Power management consumption control";
CM_ BO_ 948 "0x3B4 (DME): Power battery voltage";
CM_ BO_ 958 "0x3BE (CAS): Power running time";
CM_ BO_ 1007 "0x3EF (DME): Engine OBD data";
CM_ BO_ 1544 "0x608 [PT-CAN via ZGW — NOT direct K-CAN] DME UDS diagnostic response. PT-CAN 500 kbit/s. Physical request ID = 0x600, response = 0x608. Reachable from K-CAN tester (0x6F1) only via ZGW gateway bridge — ZGW forwards the request to PT-CAN and relays response back. Direct PT-CAN access requires dedicated MCP2515 at 500 kbit/s. Standard OBD2 Mode 01 PIDs answered on 0x7E8 via functional address 0x7DF. Source: BMW ISTA, obd2-diagnostic-architecture.md";
CM_ BO_ 1548 "0x60C [PT-CAN via ZGW — NOT direct K-CAN] EGS (ZF 6HP19 TCM) UDS diagnostic response. PT-CAN 500 kbit/s. Physical request ID = 0x604, response = 0x60C. Reachable from K-CAN only via ZGW. Holds gearbox adaptation data, clutch friction values, ATF temperature calibration. SecurityAccess (0x27) required for adaptation reset. OBD2 ATF temp PID 0x6C answered on 0x7E9. Source: obd2-diagnostic-architecture.md";
CM_ BO_ 1554 "0x612 (DME → DIA): UDS diagnostic response from DME/ECM (Digital Motor Electronics, N47D20O1 engine ECU) on K-CAN. Physical addressing: request sent to 0x6F1 (DIA tester), response from 0x612. ISO-TP transport: PCI byte in B0 (high nibble = frame type: 0=SF, 1=FF, 2=CF, 3=FC; low nibble = DL for SF or length-high for FF). UDS positive response = request service ID + 0x40 (e.g., 0x50 for 0x10 session control, 0x62 for 0x22 ReadDID). Negative response: service ID = 0x7F, B1 = requested service, B2 = NRC. Also used by DSC (0x612) on K-CAN — context depends on diagnostic session. Source: ISO 14229-1 UDS, BMW ISTA diagnostic trace, architecture doc obd2-diagnostic-architecture.md";
CM_ BO_ 1562 "0x61A [PT-CAN via ZGW — NOT direct K-CAN] DSC (ABS/Dynamic Stability Control, ATE MK60E5) UDS diagnostic response. PT-CAN 500 kbit/s. Physical request ID = 0x612, response = 0x61A. Reachable from K-CAN only via ZGW. Holds wheel speed sensor calibration, yaw sensor offset, ABS valve test routines (RoutineControl 0x31), bleeding routine. Source: obd2-diagnostic-architecture.md";
CM_ BO_ 1650 "0x672 (FRM3 → DIA): UDS diagnostic response from FRM3 (Footwell Module / Fussraummodul, revision C32) on K-CAN. CONFIRMED from Carista HIL capture: tester sends on 0x6F1 with B0=0x72 (FRM node address), FRM3 responds on CAN ID 0x672 with B0=0xF1. Address formula: response_ID = 0x600 | node_byte = 0x600 | 0x72 = 0x672. Physical request address: 0x6F1 with target byte 0x72 in B0. No security access required for DID 0x3400 (coding block) in default session. FRM controls: window lifters (all 4), exterior mirrors, footwell lighting, welcome light, rain/light sensor input, interior light relay. Key DIDs: 0x3400=lamp monitoring coding block (16 bytes), 0xF190=VIN, 0xF187=spare part number, 0xF189=SW version. Source: Carista HIL capture 2026-04-08, frm3_lamp_check_disable.md";
CM_ BO_ 1600 "0x640 (CAS → DIA): UDS diagnostic response from CAS (Car Access System / Carstarter) on K-CAN. Node 0x40 CONFIRMED from Carista HIL capture (31 response frames on 0x640). Tester request: 0x6F1 → target byte 0x40. CAS holds immobiliser data, comfort access, key learning. Programming session (0x10 0x03) required for key coding — use with extreme caution. NOTE: previous agent brief incorrectly placed CAS at 0x650 (node 0x50 = unknown, possibly CCC_GW/M-ASK area, NOT CAS).";
CM_ BO_ 1622 "0x656 (JBBF → DIA): UDS diagnostic response from JBBF/JBE (Junction Box Body Front / Junctions Box Elektronik) on K-CAN. Node 0x56 CONFIRMED from Carista HIL capture (11 response frames on 0x656, DID 0x3000 responded, 0x2E write session active). JBBF acts as K-CAN/PT-CAN gateway (ZGW function) on E90. Controls: central locking relay logic, window rear pair, heated seats, horn, footwell lighting. NCS Expert module name: JBBFE/JBBFR3. EDIABAS driver: jbbf3.prg. Node identity confirmed by user 2026-04-08. Extended session required for coding.";
CM_ BO_ 1596 "0x63C (IHKA → DIA): UDS diagnostic response from IHKA (Integrated Heating/Klimaanlage — automatic climate control) on K-CAN. Physical IHKA request ID = 0x63C, response (legacy) or 0x644 (alternate — confirm). IHKA controls AC compressor relay, evaporator blower, all temperature zone actuators. Source: obd2-diagnostic-architecture.md";
CM_ BO_ 1624 "0x658 (LM → DIA): UDS diagnostic response from LM (Light Module — E8x adaptive light unit, Lichtmodul) on K-CAN. Physical LM request ID = 0x654, response = 0x658. Controls bi-xenon swivel actuators, cornering light logic. Coding allows enabling/disabling adaptive light, DRL configuration. Source: obd2-diagnostic-architecture.md";
CM_ BO_ 1632 "0x660 (Kombi → DIA): UDS diagnostic response from Kombi (instrument cluster). Physical addressing: tester sends to 0x6F9 (Kombi request ID), Kombi responds on 0x660. ISO-TP single-frame (SF) typical for standard DID reads (VIN, SW version). Extended session required for coding access (0x10 0x02). TesterPresent (0x3E 0x00) must be sent every 2s to maintain extended session. Source: BMW ISTA, obd2-diagnostic-architecture.md";
CM_ BO_ 1640 "0x668 (SZL → DIA): UDS diagnostic response from SZL (Steering Column Switch Centre / Schaltzentrum Lenkrad) on K-CAN. Physical SZL request ID = 0x660, response = 0x668. Also contains LWS (Lenkwinkelsensor — steering angle sensor). SZL coding covers MFL button assignment and cruise control stalk function. Steering angle sensor initialisation accessible via RoutineControl. Source: obd2-diagnostic-architecture.md";
CM_ BO_ 1676 "0x68C (PDC → DIA): UDS diagnostic response from PDC (Park Distance Control) on K-CAN. Physical PDC request ID = 0x68C, response = 0x694. Hmm — confirm exact address pair from trace. PDC holds sensor distance calibration. Activation/deactivation of PDC feature via coding. Source: obd2-diagnostic-architecture.md. NOTE: request ID 0x68C confirmed in module registry; response ID 0x694 = decimal 1684 — add BO_ 1684 DIAG_RESP_694_PDC if trace confirms.";
CM_ BO_ 1777 "0x6F1 (DIA → module): UDS diagnostic request from tester (our Pico 2W IDRIVE_NEW firmware acting as diagnostic tool). This is the ISO 15765-2 / ISO 14229 tester address on BMW K-CAN. All module requests are sent from this address. For functional/broadcast addressing (default session open on all modules simultaneously), BMW uses 0x6F1 with functional target. For physical addressing, tester sends to module-specific request ID (e.g., 0x640 for FRM) but own source address remains 0x6F1. Frame format: B0 PCI, B1 UDS service ID [B2 sub-function or DID-hi, B3 DID-lo, B4-B7 data]. Source: BMW E9x diagnostic trace, ISO 14229-1";
CM_ BO_ 2015 "0x7DF [OBD2 via ZGW — NOT direct K-CAN] Functional broadcast request to all OBD2-compliant ECUs. Standard ISO 15031 / SAE J1979. All OBD2-compliant ECUs respond. On BMW E9x PT-CAN: DME responds on 0x7E8, EGS on 0x7E9. Accessible from K-CAN via ZGW gateway — ZGW forwards standard OBD2 Mode 01/03/04/09 requests to PT-CAN. NOT suitable for BMW-proprietary UDS (Mode 0x22/0x2E/0x27/0x31) — use physical addressing (0x6F1 → 0x600 etc.) for extended diagnostics. Frame format: B0=0x02 (2 bytes follow), B1=Mode (0x01=current data, 0x03=stored DTCs, 0x04=clear DTCs, 0x09=vehicle info), B2=PID/InfoType, B3-B7=0x00 padding. Source: SAE J1979, ISO 15031-5";
CM_ BO_ 2016 "0x7E0 [OBD2 via ZGW — NOT direct K-CAN] Physical OBD2 request to DME/ECM. Used when targeting only the engine ECU (not broadcast). Response on 0x7E8. Physical addressing bypasses ZGW arbitration — may not be accessible from K-CAN without dedicated PT-CAN connection. Source: ISO 15031-5";
CM_ BO_ 2017 "0x7E1 [OBD2 via ZGW — NOT direct K-CAN] Physical OBD2 request to EGS/TCM (gearbox). Response on 0x7E9. OBD2 Mode 01 PID 0x6C = ATF temperature (gearbox oil temp). Source: ISO 15031-5";
CM_ BO_ 2024 "0x7E8 [OBD2 via ZGW — NOT direct K-CAN] Standard OBD2 response from DME (engine ECU). Frame format: B0=number of additional bytes (0x03-0x06 typical), B1=Mode+0x40 (e.g. 0x41 for Mode 01 current data), B2=PID, B3=DataA, B4=DataB, B5=DataC, B6=DataD. Key Mode 01 PIDs on N47D20O1: 0x04=engine load%, 0x05=coolant temp (A-40 degC), 0x0B=intake MAP kPa, 0x0C=RPM ((256A+B)/4), 0x0D=speed km/h, 0x0F=intake air temp (A-40 degC), 0x11=throttle position A/2.55%, 0x2F=fuel level A/2.55%, 0x33=barometric pressure A kPa, 0x42=control module voltage (256A+B)/1000 V, 0x46=ambient air temp (A-40 degC). Source: SAE J1979, ISO 15031-5";
CM_ BO_ 2025 "0x7E9 [OBD2 via ZGW — NOT direct K-CAN] Standard OBD2 response from EGS (ZF 6HP19 gearbox TCM). Frame format same as 0x7E8. EGS-specific PID: 0x6C=ATF oil temperature (ZF 6HP19 confirmation PENDING — community data suggests same A-40 degC formula as DME coolant). Also responds to Mode 09 InfoType 0x02 (VIN) for EGS identity. Source: SAE J1979; ZF 6HP19 OBD2 data not confirmed on this vehicle — mark decoded values as UNVERIFIED until HIL validation.";
CM_ BO_ 417 "0x1A1 (XXX): Speed as used by instrument cluster. 5 bytes. Bytes 2-3 big-endian: ((B2*256)+B3)/100 = MPH. Source: loopybunny.co.uk/CarPC";
CM_ BO_ 612 "0x264 (ZBE — iDrive Controller): iDrive knob rotary encoder per-detent frame. B0=0xE1, B1=0xFD, B5=0x1E constants. B2=ByteCounter: shared incrementing frame-sequence counter (same counter as 0x267 B2 — both IDs share one global counter in firmware). B3=RotaryAbsoluteLow: low byte of 16-bit absolute encoder counter. B4=RotaryAbsoluteHigh: high byte of 16-bit encoder counter. Counter encoding: (B4<<8 | B3) as unsigned 16-bit. Initial/boot value [B3=0x00, B4=0x7F] = 0x7F00 = 32512 (mid-range). CW rotation = counter increments (B3++; if B3 overflows 0xFF→0x00, B4++). CCW rotation = counter decrements (B3--; if B3 underflows 0x00→0xFF, B4--). One physical detent = ±1 on counter. Event-driven: transmits only while knob is being turned; absent when knob is still. HIL-3 2026-03-24 confirmed: 'wobble' sequence B3=0xFE→0xFD (one CCW click) →0xFE (one CW click) observed; rollover 0xFF→0x00 with B4 0x7F→0x80 carry confirmed. Only appears when CIC menu is active (0x5E7 B4=0x01). Source: idCanSend.txt firmware (idrive_backup, deep-tested); HIL-3 2026-03-24";
CM_ BO_ 615 "0x267 (ZBE — iDrive Controller): iDrive button/joystick event frame. B0=0xE1, B1=0xFD constants. B2=ByteCounter: shared sequence counter (same as 0x264 B2). B3=action byte: high nibble=joystick direction (0=none,1=up,2=right,4=down,8=left), low nibble=press state (0x1=pressed/short,0x2=long-press,0x0=released). B4=area context: 0xC0=panel hard buttons, 0xDE=knob center press, 0xDD=joystick. B5=button ID: for B4=0xC0 panel buttons bitmask: 0x01=Menu/Mode, 0x02=Back, 0x04=Option, 0x08=Radio, 0x10=CD/Media, 0x20=NAV, 0x40=Tel; for B4=0xDE knob-center: B5=0x01; for B4=0xDD joystick: B5=0x00 (direction in B3 high nibble). Protocol: press sends B3=0x01 frame then after hold B3=0x00 release frame; B2 increments between press and release. Long-press of knob-center (B4=DE, B5=0x01, B3=0x02): native BMW CIC behaviour. Long-press of Menu/Mode (B4=C0, B5=0x01, B3=0x02, 3s hold): NOT native BMW behaviour — this is a custom firmware trick in idCanSend.txt (TBit=15) used to switch video output to aftermarket MMI instead of CIC; observed in HIL-3 at t=2889271ms. HIL-3 2026-03-24 confirmed: Back(C0/02), NAV(C0/20), JoyPress/enter(DE/01), Menu/Mode(C0/01), Menu long-press (C0/01 B3=0x02 = MMI video switch, non-BMW). Source: idCanSend.txt firmware (idrive_backup, deep-tested); loopybunny.co.uk/CarPC (structure); HIL-3 2026-03-24 (bitmask values)";
CM_ BO_ 246 "0x0F6: Exterior mirror control / mirror position status. Sender: KGM (Body Gateway Module, node 0x00). 2-byte, static 0xF3 0xF3 in t1.log (idle/no-command state). Follows the body-module door-status +4 sequence: 0x0E2 BFT (passenger front door), 0x0E6 BFH (passenger rear door), 0x0EA FAT (driver front door), 0x0EE FAH (driver rear door), 0x0F2 HK (boot/tailgate), 0x0F6 mirrors. Source: MorGuux BMW E90 K-CAN gist. ** IMPORTANT: Mirror motor control on E90 goes via LIN bus (FRM Footwell Module -> LIN -> mirror motor actuators). The joystick input on K-CAN may trigger an FRM frame, but the actual mirror movement commands are LIN-bus-only and will NOT appear in a K-CAN capture. 0x0F6 = 0 frames confirmed in 10-min real drive log (10minutes_run.log) even though mirror adjustments were physically performed. K-CAN only sees 0xF3 0xF3 (idle/no-command state) periodically. To capture mirror commands: tap LIN bus at FRM connector, or read mirror position via UDS (0x7C3 FRM diagnostic frames observed at ts=76575-78642ms before vehicle movement may be position readout). **";
CM_ BO_ 494 "0x1EE (FRM — Footwell Module): Indicator / turn signal stalk position. Byte 0: 0=off, 1=up1st, 2=up2nd, 4=down1st, 8=down2nd, 16=full beam, 32=flash. Byte 1=0xFF. Source: loopybunny.co.uk/CarPC";
CM_ BO_ 950 "0x3B6 (FRM — Footwell Module): FL (driver front) Window position feedback. WindowPosition(B0): 0=closed to 87=fully open. WindowMovement(B1): 0xFC=closed, 0xFD=moving, 0xFE=open. WindowMotionFlags(B2): motion state bits. HIL-validated from Windows_cycle.log";
CM_ BO_ 951 "0x3B7 (Gate1): RL (driver rear) Window position feedback. WindowPosition(B0): 0=closed to 87=fully open. WindowMovement(B1): 0xFC=closed, 0xFD=moving, 0xFE=open. WindowMotionFlags(B2): motion state bits. HIL-validated from Windows_cycle.log (limited data captured)";
CM_ BO_ 952 "0x3B8 (FRM — Footwell Module): FR (passenger front) Window position feedback. WindowPosition(B0): 0=closed to 87=fully open. WindowMovement(B1): 0xFC=closed, 0xFD=moving, 0xFE=open. WindowMotionFlags(B2): motion state bits. HIL-validated from Windows_cycle.log";
CM_ BO_ 953 "0x3B9 (Gate1): RR (passenger rear) Window position feedback. WindowPosition(B0): 0=closed to 87=fully open. WindowMovement(B1): 0xFC=closed, 0xFD=moving, 0xFE=open. WindowMotionFlags(B2): motion state bits. HIL-validated from Windows_cycle.log (no data on this HIL setup)";
CM_ BO_ 570 "0x23A (CAS or CIC gateway): Keyfob/CIC interaction state. B3=0x60 constant. B1 state: 0x30=idle/home, 0x33=active menu/CIC interaction ongoing. B2 countdown: 0x04→0x01→0x00 during startup init; 0x00 during normal operation. HIL-3 2026-03-24: B1 transitions 0x30→0x33 within 5ms of MENU hard button release (t=2365334ms), confirming B1=0x33 marks CIC menu mode active. Also B2 runs 0x04→0x00 countdown at both session start AND session end (shutdown). Loopybunny source labels B2 as keyfob button command (0x04=lock, 0x01=unlock) — this appears incorrect for CIC-equipped E90 LCI; in our data B2 is an init/deinit counter, not a keyfob command. Source: loopybunny.co.uk/CarPC (partial); HIL-3 2026-03-24 (override)";
CM_ BO_ 586 "0x24A (PDC): Reverse gear status from FRM. Byte 0: 5=in reverse, 6=not in reverse; 2s period. Source: loopybunny.co.uk/CarPC";
CM_ BO_ 594 "0x252 (Gate1): Wiper status. Byte 0: 0xCE=down/parked, 0xCD=going up. Source: loopybunny.co.uk/CarPC";
CM_ BO_ 622 "0x26E (ZBE — iDrive controller): ZBE mode-state heartbeat, 2-second periodic. NOT the rotary encoder (encoder is 0x264). B3=0x00, B5-B7=0xFF constants. B2 mode flag: 0x3F=home/idle (bit6=0), 0x7F=CIC menu active (bit6=1 — transition observed at t=2375221ms during menu session). B1: 0x00=pre-menu idle, 0x40=menu interaction acknowledged (~22s after menu entry). B0: 0x00=idle, 0x40=extended/sustained menu state. Loopybunny source mislabels this as 'RotaryAbsolute per-notch counter' — incorrect for E90 LCI CIC; B2 is a 2-state flag, not a counter. Source: HIL-3 2026-03-24 (override)";
CM_ BO_ 714 "0x2CA (Kombi): Outside ambient temperature. Byte 0: (value-80)/2 = degC; byte 1=0xFF. Source: loopybunny.co.uk/CarPC";
CM_ BO_ 721 "0x2D1 (FZD — Roof Functions Centre): Attributed to FZD (Dachfunktionszentrum — overhead console module). B0: slowly-varying temperature-like signal, range 0x83-0x9E (131-158 raw) in intensive driving session. Formula raw-48=degC gives 83-110 degC range, consistent with solar/IR-heated interior surface (headliner area) or FZD-mounted temperature sensor. At drive start: 0x9E=110C declining to 0x83=83C over ~110s, then stabilising ~83-87C (ambient cabin normalisation). N.B.: formula raw-48 is the same as DME TEMP_ENG/TEMP_EOI — possibly shared ECU convention. DBC name 'Status_fitting_window_V' (Verglasung) may refer to glazing/glass temperature rather than mechanical window status. B1=0xF8 fixed (0xF8 = common 'data valid' marker in K-CAN). No signals currently defined in DBC — signal decode unconfirmed, requires dedicated HIL session. Source: HIL intensive driving 2026-03-29";
CM_ BO_ 725 "0x2D5 (Gate1): Rear window heater status. B0 bit0=RearWindowHeater (0xFC=off, 0xFD=on). Source: clima_modes_bottom_up.log HIL capture (ON at t=40.87s, OFF at t=43.87s)";
CM_ BO_ 726 "0x2D6 (Gate1): AC compressor valve status. Byte 1: 252=off, 253=on. Source: loopybunny.co.uk/CarPC";
CM_ BO_ 742 "0x2E6 (IHKA — Automatic Climate Control): Climate air distribution — driver side (FA = Fahrerseite). B7=ClimateTemp actual driver zone output (raw/2 degC, e.g. 0x20=16C, 0x38=28C). B5=FanSpeed 1-7 (AUTO=0 not observed, min seen=1). B0/B1/B2=air distribution percentages for 3 vents: observed patterns: 0x28/0x32/0x64=default mix, 0x3C/0x64/0x00=floor-dominant, 0x2D/0x00/0x64=center-face, 0x00/0x3C/0x64=window mode, 0x64/0x00/0x00+B5=7=defrost, 0x00/0x64/0x00+B5=7=MAX AC. B3=0x29 constant. B6 bit6 set in MAX AC mode (0x7F vs 0x3F). Confirmed independent from passenger zone (0x2EA): driver stays fixed when only passenger zone adjusted. Source: clima_temp_fan.log + clima_modes_bottom_up.log HIL captures";
CM_ BO_ 746 "0x2EA (IHKA — Automatic Climate Control): Climate air distribution — passenger side (BF = Beifahrerseite). B7=ClimateTempPassenger actual passenger zone output (raw/2 degC, same scale as 0x2E6). Confirmed independent from driver zone: rises separately when only left/passenger knob is adjusted. Source: clima_temp_fan.log HIL capture";
CM_ BO_ 752 "0x2F0: [HYPOTHESIS — UNVERIFIED] Original DBC: Status_air_condition_functions, sender IHKA, 8 bytes. CONFLICT: 10minutes_run.log shows DLC=2, payload always F7 FC (100% static across 195 frames, period ~2000 ms, no variation during or after mirror adjustments). DBC DLC claim of 8 bytes does not match observed DLC=2. Copilot hypothesis: Mirror Status from TSG (door module) to FRM3 — bit0=MirrorMoveActive, bits1-2=MirrorMoveDirection, bit3=MirrorSelect, bit4=MirrorHeaterStatus, bit5=MirrorFault. This hypothesis is NOT supported by the drive log: payload never changes from F7 FC even when mirrors were physically adjusted. Static heartbeat behaviour is inconsistent with a movement-status frame. True identity unknown — needs HIL capture with known sender isolation.";
CM_ BO_ 753 "0x2F1: [HYPOTHESIS — UNVERIFIED] Original DBC: Status_driver_detection, sender MRSZ (occupant detection / airbag), 3 bytes — DLC matches observed DLC=3. 10minutes_run.log: 412 frames, period ~1000 ms. B0 and B1 are rolling counters (incrementing mod 256, loosely correlated). B2 alternates FC/FD. Rolling counter pattern is consistent with a periodic MRSZ heartbeat — NOT consistent with Copilot hypothesis of Mirror Command (button press bits from TSG). Copilot hypothesis claims bit0=AdjustUp, bit1=AdjustDown, bit2=AdjustLeft, bit3=AdjustRight, bit4=SelectLeft, bit5=SelectRight — payload structure (counter + counter + status nibble) does not match button-press bitmask semantics. Most likely this is genuine MRSZ occupant detection status. Needs HIL confirmation.";
CM_ SG_ 714 OutsideTemp "Byte 0: (raw-80)/2 = degC. Encoded as (degC*2)+80. DBC uses factor=0.5, offset=-40.";
CM_ SG_ 842 Longitude "32-bit signed raw. Decode: value / 11930464.71 - 360 = decimal degrees";
CM_ SG_ 842 Latitude "32-bit signed raw. Decode: value / 11930464.71 = decimal degrees";
CM_ SG_ 944 ReverseGear_3B0 "Byte 1: 0xFD=not in reverse, 0xFE=in reverse";
CM_ SG_ 586 ReverseGear_24A "Byte 0: 5=in reverse, 6=not in reverse";
CM_ BO_ 481 "0x1E1 (XXX): Counter and Door Status, sent every 200ms. Bytes 0-1 rolling counter (211-225 normal, 36-50/240-254 engine starting). Byte 2 door open bitmask: b0=driver, b2=passenger, b4=rear driver, b6=rear passenger. Bytes 3-5 padding 0xFF. Source: loopybunny.co.uk/CarPC";
CM_ BO_ 627 "0x273 (CCC — Car Communication Computer / CIC): CIC state event counter. B1=0xE1, B2=0x00, B3=0xF0, B4=0xFF, B5=0x7F, B6=0xDE constant. B7 = global event counter, increments by 1 on each significant CIC menu state transition (enter submenu, back-to-menu, mode change). NOT a per-knob-detent counter — too infrequent (~11 events over 9.8 min). B0 flag byte: 0x1D=normal CIC interaction, 0x5D=rapid/held interaction (bit6 set, observed during 78-92ms rapid button burst at t=2857995-2858165ms). HIL-3 2026-03-24: first 4 counter events at t=2365659-2375390ms coincide exactly with CIC menu navigation session (3 events ~250-750ms apart = scrolling through items; 4th event after 8.7s gap = returned from submenu). Counter range 0x01-0x0C observed in 9.8 min log. ID already referenced by CM_ BO_ 631 (0x277 = reply frame). Source: HIL-3 2026-03-24 (10minutes_run_Wheel_doors_tests.log)";
CM_ BO_ 631 "0x277 (ZBE — iDrive controller reply to CCC 0x273): CIC screen/state acknowledgement frame. B0=0xE1, B1=0x9D (may encode active screen/context — constant at 0x9D throughout HIL-3 main-menu session), B3=0xFF constants. B2 = event counter echo: mirrors B7 of the triggering 0x273 frame (same value, confirms handshake). Sends 1-3 frames per 0x273 event at ~160ms intervals. First 0x277 frame arrives at the same millisecond as the 0x273 event. HIL-3 2026-03-24: B2 range 0x01-0x0C, skips values that arrived too close together (0x07 skipped when two 0x273 events fired 92ms apart). B1=0x9D may change per screen context — all observations in this log are within the same menu session so a different B1 value would indicate a different CIC screen. Source: loopybunny.co.uk/CarPC (extended); HIL-3 2026-03-24";
CM_ BO_ 632 "0x278 (CIC): Unknown CIC/NavGraph group message. DLC 8. B0: 7-bit rolling counter (0x0A-0x7E, 117 steps, shared with 0x3CC/0x3F7 — all three counters step in lockstep). B2: 12-step cycle counter (0x00-0x0B). B6: 6 observed values (0x1E=30, 0x29=41, 0x2E=46, 0x32=50, 0x3A=58, 0x3B=59) — temperature in degC (coolant or ambient as reported by CIC). B0/B1 vary proportionally (often within 1 unit of each other, occasionally diverge — may be paired sensor readings). Sender is CIC (iDrive CCC/NBT — same ID-space as 0x273 CIC_Status, 0x277 Idrive_Emu_Response, 0x27A NavGraph_Sync). Source: HIL intensive driving logs 2026-03-29";
CM_ BO_ 634 "0x27A: Navigation Graph Sync. Sender: CCC_GW (iDrive CCC Gateway). DLC 4. Source: rusefi.com BMW E65 Tool32 K-CAN table";
CM_ BO_ 840 "0x348: Navigation Graph Alignment. Sender: CCC_GW (iDrive CCC Gateway). DLC 4. Source: rusefi.com BMW E65 Tool32 K-CAN table";
CM_ BO_ 844 "0x34C: Navigation GPS 2. Sender: CCC_GW. DLC 5. Source: rusefi.com BMW E65 Tool32 K-CAN table";
CM_ BO_ 972 "0x3CC (CCC_GW): NavGraph group dormant message. DLC 7. B0: rolling counter shared with 0x278/0x3F7 (7-bit, 0x0A-0x7E). B1=0xF6, B2-B4=0xFE fixed (data not available). B5: varies 0x00-0xFF (purpose unknown). B6: 3 states (0xF0, 0xF7, 0xFF — likely status flags). Consistently present in all driving sessions. Source: HIL 2026-03-29";
CM_ BO_ 1015 "0x3F7 (CCC_GW): NavGraph group dormant message. DLC 8. B0: rolling counter shared with 0x278/0x3CC. B1: 3 states (0xE2, 0xE6, 0xEE). B3: 2 states (0x7F, 0xFF). B4: 2 states (0x15, 0xFF). Most bytes fixed 0xFF/0xFE. Mostly inactive — likely GPS or nav sub-message dormant when no active navigation. Source: HIL 2026-03-29";
CM_ BO_ 1009 "0x3F1: Extended Lighting Personalisation Status (CKM — Comfort Coding Module data). Sender: LM/FRM (Light Module / Footwell Module, node 0x70). Paired with 0x3F0 (Extended Lighting Personalisation Configuration from CCC_GW). Appears once at startup — FRM broadcasts current extended-lighting personalisation state. Source: MorGuux BMW E90 K-CAN gist (entry: 1009,0x3F1,Status Light Extended CKM [1],112,0x70,LM)";
CM_ BO_ 1043 "0x413 (FRM — Footwell Module): Lamp status broadcast, ~1 s period. Normal startup: valid from +326ms, stable 49 8E 97 86 62 77 E9 87 throughout ignition-on cycle. Fault startup: FF FF FF FF FF FF FF FF from +5.5s (lamp check incomplete / bulb missing), resolves to normal value only after ~25s once FRM completes fault detection. FF FF pattern is a reliable indicator that FRM has not yet confirmed lamp integrity. Byte layout not yet decoded at bit level. Source: HIL 2026-03-20 (driving), HIL 2026-05-03 (low-beam fault comparison).";
CM_ BO_ 1045 "0x415 (FRM — Footwell Module): Lamp status broadcast companion to 0x413, ~1 s period, DLC=7. Normal startup: B0=0x41 for first 2 frames (init step), then locks to 0x42 E7 81 32 F0 00 80 (B0 bits[1:0] increment once at startup, not a rolling counter). Fault startup: FF FF FF FF FF FF FF from +5.5s, resolves at +25s same as 0x413. B0 InitCounter (bits [1:0]): 0x01=initialising, 0x02=ready. Source: HIL 2026-03-20 (driving), HIL 2026-05-03 (low-beam fault comparison).";
CM_ BO_ 1153 "0x481: BMW K-CAN Network Management alive frame — ACSM (Airbag Control Module, node 0x01). Source: MorGuux E90 K-CAN gist";
CM_ BO_ 1216 "0x4C0 (XXX): BMW K-CAN Network Management alive message (52 frames); seen in t1.log";
CM_ BO_ 1238 "0x4D6 (XXX): BMW K-CAN Network Management alive message (53 frames); seen in t1.log";
CM_ BO_ 1248 "0x4E0: BMW K-CAN Network Management alive frame — Kombi (instrument cluster, node 0x60). Source: MorGuux E90 K-CAN gist";
CM_ BO_ 1250 "0x4E2: BMW K-CAN Network Management alive frame — CCC_GW/M_ASK (iDrive CCC gateway, node 0x62). Source: MorGuux E90 K-CAN gist";
CM_ BO_ 1255 "0x4E7 (XXX): BMW K-CAN Network Management alive message (55 frames); seen in t1.log";
CM_ BO_ 1266 "0x4F2 (XXX): BMW K-CAN Network Management alive message (56 frames); seen in t1.log";
CM_ BO_ 1267 "0x4F3 (XXX): BMW K-CAN Network Management alive message (56 frames); seen in t1.log";
CM_ BO_ 1272 "0x4F8 (XXX): BMW K-CAN Network Management alive message (51 frames); seen in t1.log";
CM_ BO_ 1409 "0x581: BMW K-CAN Services frame — ACSM (Airbag Control Module, node 0x01). Also carries seatbelt indicator: byte 3 bit 0 = 0x28=light off, 0x29=light on. Source: loopybunny.co.uk/CarPC, MorGuux E90 K-CAN gist";
CM_ BO_ 1472 "0x5C0: BMW K-CAN Services frame — CAS (Car Access System, node 0x40). Source: MorGuux E90 K-CAN gist";
CM_ BO_ 1494 "0x5D6 (XXX): BMW K-CAN Services range message, rare (2 frames); seen in t1.log";
CM_ BO_ 1506 "0x5E2 (ZBE — iDrive controller): Dual-role frame. (1) BUTTON EVENT (normal operation): B0=0x01, B1=0x03=pressed/0x02=released, B2=variable, B3-B7=0xFF. Event-driven on state change, two frames 10ms apart per press (debounce). Most likely MENU/NAV/TEL hard button. (2) FAULT NOTIFICATION (lamp fault only): B0=0x01, B1 alternates 0x02/0x03 (channel), B2=varying message code (CIC text message ID), B3-B7=0xFF. Appears at +9.7s in fault startup — 2 rapid frames (10ms) for left and right low beam separately, then further frames at ~500ms intervals as CIC renders messages. Absent in normal startup. The B1=0x02/0x03 alternation in fault context likely encodes different CIC display channels rather than button state. Source: HIL-3 2026-03-24 (button), HIL 2026-05-03 (low-beam fault).";
CM_ BO_ 1511 "0x5E7 (ZBE — iDrive controller): ZBE operational state heartbeat, 2-second period. B0=0x99, B1=0xE1, B2=0xFE constant. B3 = rolling counter (increments +1 per 2s transmission). B4 = CIC/menu state flag: 0x06=home/idle screen (no active menu interaction), 0x01=CIC menu active (changed from 0x06 to 0x01 at t=2366232ms, ~4s after MENU hard button press). B5-B7=0xFF constant. HIL-3 2026-03-24: B4 remained 0x01 for the rest of the log after menu was entered (never returned to 0x06 within 9.8 min log). Source: HIL-3 2026-03-24 (10minutes_run_Wheel_doors_tests.log)";
CM_ BO_ 1528 "0x5F8 (XXX): BMW K-CAN Services range message (11 frames); seen in t1.log";
CM_ BO_ 672 "0x2A0 (CAS): Central locking control. Three frame types on same ID. (1) HEARTBEAT (~5s periodic): B0=B1=B2=0x88. B3=0x01 static. B4=rolling counter (increments by 2 per cycle, CAS auto-increments correctly regardless of injected commands). B5/B6/B7=current lock state (see below). Sending 88 88 88 wakes bus ~20s but triggers no action. (2) COMMAND BURST (3 rapid frames on keyfob/button press): B0=B1=command byte, B2=modifier. Command bytes: 0x11=unlock, 0x22=lock. B2=0x80 identifies trunk command (pattern: xx xx 80; B0=B1=0x88 for trunk burst). B3=central lock panic-disable: 0x00=enabled(normal), 0x04=disabled(panic lockout). NOTE: 10x rapid toggle triggers ~1min lockout of both cabin button and keyfob. (3) TRUNK: identified by B2=0x80. B5/B6/B7 lock state encoding (CONFIRMED HIL 2026-04-08): 0x40 0x06 0x00=unlocked by keyfob (simple), 0x44 0x05 0x04=locked by keyfob (simple), 0x84 0x02 0x00=comfort open by keyfob (windows opened), 0x84 0x02 0x04=comfort close by keyfob (windows closed), 0x40 0x0B 0x00=interior button unlock, 0x43 0x0B 0x03=interior button lock, 0x?? 0x0B 0xx=interior button (general pattern: B6=0x0B). Trunk lock state: B5=0x80. Interior cabin button and trunk button are NOT on K-CAN — CAS blocks K-CAN button signals after real keyfob lock. Sleep state (post ignition-off): B5/B6/B7=44 05 04. Per-door status NOT in this frame — see 0x0E2/0x0E6/0x0EA/0x0EE. Source: HIL 2026-03-22/23/24/2026-04-07/08.";
CM_ SG_ 672 LockCmd_B0 "Primary command byte. HEARTBEAT: 0x88. COMMAND BURST: 0x11=unlock, 0x22=lock, 0x88=trunk burst. Always identical to LockCmd_B1.";
CM_ SG_ 672 LockCmd_B1 "Mirror of LockCmd_B0 in all frame types.";
CM_ SG_ 672 LockCmd_B2 "Command modifier / frame type discriminator. HEARTBEAT: 0x88. TRUNK COMMAND: 0x80 — B2=0x80 is the definitive trunk identifier (pattern xx xx 80). Other command modifier values not yet confirmed.";
CM_ SG_ 672 LockState_B3 "Central lock panic-disable flag. HEARTBEAT: 0x01 static. COMMAND BURST: 0x00=lock enabled (normal), 0x04=lock disabled by panic (10x rapid toggle triggers ~1 min lockout of keyfob and cabin button).";
CM_ SG_ 672 LockState_B4 "Rolling heartbeat counter (CONFIRMED HIL 2026-04-08). Increments by 2 per cycle. CAS auto-increments correctly regardless of injected commands. NOT a lock state byte.";
CM_ SG_ 672 LockState_B5 "Lock action byte (CONFIRMED HIL 2026-04-08). 0x40=keyfob simple unlock OR interior button unlock, 0x43=interior button lock, 0x44=keyfob simple lock, 0x84=keyfob comfort (both open and close), 0x80=trunk state. Sleep state (post ignition-off): 0x44.";
CM_ SG_ 672 LockState_B6 "Lock source/detail byte (CONFIRMED HIL 2026-04-08). 0x06=keyfob simple unlock, 0x05=keyfob simple lock, 0x02=keyfob comfort (both open and close), 0x0B=interior cabin button (both lock and unlock). Sleep state: 0x05.";
CM_ SG_ 672 LockState_B7 "Lock result byte (CONFIRMED HIL 2026-04-08). 0x00=unlocked (keyfob or interior button), 0x03=interior button lock, 0x04=keyfob lock. Sleep state: 0x04.";
CM_ BO_ 1987 "0x7C3: CAS Application Message 2. Sender: CAS (Car Access System) / end-of-line calibration tool. Trace DLC=8 (E65 table says DLC=3, loopybunny says DLC=8 — 8 retained from trace). Keyfob security, comfort and CBS (Condition Based Service) data; byte 0 always 0xE2 in t1.log. Sources: loopybunny.co.uk/CarPC, rusefi.com BMW E65 Tool32 K-CAN table";

VAL_ 168 ST_TORQ_AVL 0 "intervention request executed" 1 "intervention ignition request not executed" 2 "intervention injection request not executed" 3 "intervention ignition and injection request not executed" 15 "signal invalid";
VAL_ 168 ST_RCPT_ENG_ACC 0 "status okay" 1 "plausibility/activity error" 2 "timeout error";
VAL_ 168 ST_RCPT_ENG_ARS 0 "status okay" 1 "plausibility/activity error" 2 "timeout error";
VAL_ 168 ST_RCPT_ENG_DSC 0 "status okay" 1 "plausibility/activity error" 2 "timeout error";
VAL_ 168 ST_RCPT_ENG_EGS 0 "status okay" 1 "plausibility/activity error" 2 "timeout error";
VAL_ 181 ST_OTMP_GRB 0 "no request" 1 "cooling request, stage1" 2 "cooling request, stage1" 3 "signal invalid";
VAL_ 181 ST_OBD_GRB 0 "STATE_ETCU_OBD = MIL_OFF" 2 "STATE_ETCU_OBD = MIL_OFF" 4 "STATE_ETCU_OBD = MIL_ON" 6 "STATE_ETCU_OBD = MIL_ON" 8 "STATE_ETCU_OBD = MIL_FLL" 10 "STATE_ETCU_OBD = MIL_FLL" 12 "STATE_ETCU_OBD = IDLE" 14 "STATE_ETCU_OBD = INI_VALUE" 15 "signal invalid";
VAL_ 181 ST_OBD_ERR_GRB 0 "NO_OBD_ERROR" 1 "OBD_ERROR" 2 "signal invalid";
VAL_ 181 ST_LIM_STORQ 0 "NO_INTERVENTION" 1 "INTERVENTION";
VAL_ 181 TORQ_DRAW_GRB 255 "signal invalid";
VAL_ 182 ST_TORQ_TAR_DSC 0 "no intervention" 1 "ASR intervention - increase torque" 2 "MSR intervention - decrease torque" 3 "signal invalid";
VAL_ 183 ST_TORQ_TAR_ACC 0 "no intervention" 1 "increase torque" 2 "signal invalid" 3 "signal invalid";
VAL_ 183 RQ_PREV_INFS_ACC 0 "no request" 1 "request over-run-fuel-shutoff inhibition" 3 "signal invalid";
VAL_ 183 ST_ACC_SWO_SYS_DME 1 "system off" 2 "system ok" 3 "signal invalid";
VAL_ 183 ST_ACC_MOD_DME 0 "passive" 1 "standby" 2 "normal" 4 "brake active" 5 "driver has stepped over" 7 "signal invalid";
VAL_ 191 STATE_DI_PUC 0 "allow fuel-shutoff" 1 "inhibit fuel-shutoff";
VAL_ 191 STATE_SP_DYN_WHEEL 0 "no request" 4 "follow torque request" 5 "fast torque adjustment" 6 "fast torque adjustment" 7 "invalid";
VAL_ 191 WMOM_PT_TAR 65535 "off";
VAL_ 191 ST_DRASY_PT 0 "no request" 1 "comfort" 3 "aggressive" 4 "driver kicks-in" 15 "error";
VAL_ 191 WMOM_PT_ENBL 0 "no request" 1 "request torque intervention" 3 "signal invalid";
VAL_ 191 RQ_GSI_CLCTR_LN 0 "no request" 1 "request gear shift indicator" 3 "unavailable";
VAL_ 408 ShifterPosition 1 "D" 2 "S" 3 "N" 4 "R" 5 "P";
VAL_ 464 ST_ENG_RUN 3 "signal invalid" 2 "engine running" 1 "engine starting" 0 "engine off";
VAL_ 464 ST_SW_WAUP 3 "signal invalid" 2 "EGS forced switching active" 1 "engine warm" 0 "warming up";
VAL_ 464 CTR_SLCK 3 "signal invalid" 2 "requirement Shiftlock" 1 "no requirement Shiftlock" 0 "not allowed";
VAL_ 466 ShiftLeverPosition 0 "Off" 1 "P" 2 "R" 4 "N" 8 "D";
VAL_ 466 ShiftLeverMode 0 "Normal" 1 "Sport" 2 "Manual";
VAL_ 466 SportButtonState 0 "Inactive" 1 "Active";
VAL_ 1409 SeatbeltLightOn 0 "Off" 1 "On";
VAL_ 226 DoorLockStatus_BFT 129 "Unlocked" 130 "Locked" 131 "Locked_Alarm";
VAL_ 226 DoorOpenStatus_BFT 252 "Closed" 253 "Open";
VAL_ 230 DoorLockStatus_BFTH 129 "Unlocked" 130 "Locked" 131 "Locked_Alarm";
VAL_ 230 DoorOpenStatus_BFTH 252 "Closed" 253 "Open";
VAL_ 234 DoorLockStatus_FAT 129 "Unlocked" 130 "Locked" 131 "Locked_Alarm";
VAL_ 234 DoorOpenStatus_FAT 252 "Closed" 253 "Open";
VAL_ 238 DoorLockStatus_FATH 129 "Unlocked" 130 "Locked" 131 "Locked_Alarm";
VAL_ 238 DoorOpenStatus_FATH 252 "Closed" 253 "Open";
VAL_ 242 BootLockStatus 241 "Unlocked" 242 "Locked" 243 "Locked_Alarm";
VAL_ 242 BootReleaseButton 135 "NotPressed" 136 "Pressed";
VAL_ 242 BootOpenStatus 192 "Closed" 193 "Open";
VAL_ 615 ButtonArea_267 222 "Direction_Or_Menu" 221 "Joystick_Direction" 192 "MultiButton";
VAL_ 615 ButtonSelect_267 0 "Direction" 1 "Menu" 2 "Back" 4 "Option" 8 "Radio" 16 "CD" 32 "Nav" 64 "Tel";
VAL_ 494 IndicatorStalkPos 0 "off" 1 "up1st" 2 "up2nd" 4 "down1st" 8 "down2nd" 16 "full_beam" 32 "flash";
VAL_ 538 LightsByte0 0 "all_off" 4 "sidelights" 5 "dip" 7 "main" 39 "fog";
VAL_ 538 LightsByte1 0 "all_off" 1 "reverse_tail" 16 "interior" 18 "interior_exterior";
VAL_ 570 KeyfobButton 0 "none" 1 "unlock" 4 "lock" 16 "boot_unlock";
VAL_ 578 MaxACMode 0 "off" 1 "on";
VAL_ 578 RecircAuto 0 "off" 1 "on";
VAL_ 578 RecircManual 0 "off" 1 "on";
VAL_ 578 AC_Compressor_578 0 "off" 1 "on";
VAL_ 586 ReverseGear_24A 5 "in_reverse" 6 "not_in_reverse";
VAL_ 594 WiperStatus 206 "parked" 205 "going_up";
VAL_ 725 RearWindowHeater 0 "off" 1 "on";
VAL_ 726 ACStatus 252 "off" 253 "on";
VAL_ 764 DriverDoorOpen 0 "closed" 1 "open";
VAL_ 764 PassengerDoorOpen 0 "closed" 1 "open";
VAL_ 764 RearDriverDoorOpen 0 "closed" 1 "open";
VAL_ 764 RearPassengerDoorOpen 0 "closed" 1 "open";
VAL_ 764 BootOpen 0 "closed" 1 "open";
VAL_ 764 BonnetOpen 0 "closed" 1 "open";
VAL_ 944 ReverseGear_3B0 253 "not_in_reverse" 254 "in_reverse";
VAL_ 678 WiperSpeedMode 0 "off" 1 "interval_1" 2 "interval_2" 3 "slow";
VAL_ 678 WiperAutoActive 0 "off" 1 "auto";
VAL_ 758 FZD_InteriorState 0 "all_off" 1 "courtesy_fade" 68 "rear_on" 84 "front_rear_on" 85 "all_on_entry";
VAL_ 772 GearDisplay 193 "Gear1_Sport" 194 "Reverse" 195 "PR_Transient" 197 "Gear1" 198 "Gear2" 199 "Gear3" 200 "Gear4" 201 "Gear5" 202 "Gear6" 209 "Neutral" 225 "RP_Transient" 227 "Park";
VAL_ 847 Handbrake_pushed_down 0 "lever_up" 1 "lever_down";
VAL_ 847 Handbrake_pulled_up 0 "lever_down" 1 "lever_up";
VAL_ 950 WindowMovement 252 "closed" 253 "moving" 254 "open";
VAL_ 951 WindowMovement 252 "closed" 253 "moving" 254 "open";
VAL_ 952 WindowMovement 252 "closed" 253 "moving" 254 "open";
VAL_ 953 WindowMovement 252 "closed" 253 "moving" 254 "open";
VAL_ 672 LockCmd_B0 17 "Unlock" 34 "Lock" 136 "TrunkOpen";
VAL_ 672 LockCmd_B1 17 "Unlock_mirror" 34 "Lock_mirror" 136 "TrunkOpen_mirror";
VAL_ 672 LockCmd_B2 24 "Unlock_0x18" 40 "Lock_0x28" 128 "TrunkOpen_0x80";
VAL_ 1777 ISOTP_PCI 0 "SingleFrame" 1 "FirstFrame" 2 "ConsecutiveFrame" 3 "FlowControl_CTS" 4 "FlowControl_Wait" 5 "FlowControl_Overflow" ;
VAL_ 1554 ISOTP_PCI 0 "SingleFrame" 1 "FirstFrame" 2 "ConsecutiveFrame" 3 "FlowControl_CTS" 4 "FlowControl_Wait" 5 "FlowControl_Overflow" ;
VAL_ 1632 ISOTP_PCI 0 "SingleFrame" 1 "FirstFrame" 2 "ConsecutiveFrame" 3 "FlowControl_CTS" 4 "FlowControl_Wait" 5 "FlowControl_Overflow" ;
VAL_ 1777 UDS_ServiceId 16 "DiagnosticSessionControl_0x10" 17 "ECUReset_0x11" 20 "ClearDTC_0x14" 25 "ReadDTCInfo_0x19" 34 "ReadDataByIdentifier_0x22" 35 "ReadMemByAddress_0x23" 39 "SecurityAccess_0x27" 40 "CommunicationControl_0x28" 46 "WriteDataByIdentifier_0x2E" 49 "RoutineControl_0x31" 52 "RequestDownload_0x34" 54 "TransferData_0x36" 55 "RequestTransferExit_0x37" 62 "TesterPresent_0x3E" 127 "NegativeResponse_0x7F" 133 "ControlDTCSetting_0x85" ;
VAL_ 1777 UDS_SubFunction 1 "DefaultSession" 2 "ExtendedDiagnosticSession" 3 "ProgrammingSession" ;
VAL_ 2015 OBD2_Mode 1 "Mode01_CurrentData" 2 "Mode02_FreezeFrame" 3 "Mode03_StoredDTCs" 4 "Mode04_ClearDTCs" 5 "Mode05_O2MonitorResults" 6 "Mode06_OnboardMonitor" 7 "Mode07_PendingDTCs" 9 "Mode09_VehicleInfo" ;
VAL_ 2024 OBD2_ModeResp 65 "Mode01_Response_0x41" 66 "Mode02_Response_0x42" 67 "Mode03_Response_0x43" 70 "Mode06_Response_0x46" 71 "Mode07_Response_0x47" 73 "Mode09_Response_0x49" ;

BA_DEF_  "DatabaseVersion" STRING ;
BA_DEF_  "BusType" STRING ;
BA_DEF_  "ProtocolType" STRING ;
BA_DEF_ BO_ "VFrameFormat" ENUM  "StandardCAN","ExtendedCAN","StandardFD","ExtendedFD","J1939PG" ;
BA_DEF_ BO_ "GenMsgEVName" STRING ;

BA_DEF_DEF_ "DatabaseVersion" "" ;
BA_DEF_DEF_ "BusType" "" ;
BA_DEF_DEF_ "ProtocolType" "CAN" ;
BA_DEF_DEF_ "VFrameFormat" "StandardCAN" ;
BA_DEF_DEF_ "GenMsgEVName" "Env@Nodename_@Signame" ;

BA_ "DatabaseVersion" "bmw_e9x_e8x1_merged_2026-03-19" ;
BA_ "BusType" "KCAN" ;
